VERSION ""

NS_ :

BS_:

BU_: STEERING_WHEEL HANDCART ECU TLM CHARGER ECU ECU HANDCART ECU LV CHARGER STEERING_WHEEL TLM HANDCART ECU HV CHARGER ECU HV HANDCART STEERING_WHEEL HV CHARGER ECU ECU HV ECU HV HANDCART ECU INVERTER_L HV HANDCART TLM ECU HV ECU HANDCART ECU TLM HV HANDCART ECU ECU HV ECU HANDCART HANDCART INVERTER_L ECU HANDCART HANDCART INVERTER_L HV HV ECU HV ECU INVERTER_L ECU HANDCART ECU HANDCART HV LV HV ECU LV ECU HANDCART LV HANDCART LV HV LV ECU LV HANDCART LV HV HV ECU HV HANDCART HV TLM TLM HV HV HV ECU HV HANDCART HV HV HV HV ECU HV HV HV TLM HANDCART ECU HV TLM HV ECU HV ECU TLM STEERING_WHEEL ECU HANDCART ECU HV ANY LV ANY ECU ANY LV ANY LV ANY STEERING_WHEEL ANY LV HV TLM LV HV TLM LV HV STEERING_WHEEL HV LV HV STEERING_WHEEL HV LV HV HV LV HV HANDCART ECU TLM CHARGER LV HV CHARGER LV HV HANDCART ECU TLM HANDCART LV HV CHARGER ECU HV CHARGER LV TLM HANDCART ECU HV CHARGER LV HV HANDCART ECU TLM CHARGER TLM HV HANDCART STEERING_WHEEL TLM CHARGER LV LV HANDCART HV LV TLM CHARGER LV LV HANDCART ECU TLM CHARGER ECU LV HANDCART LV TLM CHARGER TLM ECU HANDCART STEERING_WHEEL TLM HANDCART HANDCART ECU CHARGER HANDCART TLM HANDCART TLM ECU CHARGER HANDCART TLM HANDCART ECU STEERING_WHEEL CHARGER STEERING_WHEEL TLM CHARGER ECU STEERING_WHEEL HANDCART ECU TLM CHARGER ECU STEERING_WHEEL

BO_ 1818 NLG5_DIAG_TX: 8 NLG5
 SG_ LAD_D_ParamRp : 7|64@0+ (1,0) [0|0] "" Vector__XXX

BO_ 1816 NLG5_DIAG_RX: 8 Control
 SG_ LAD_D_ParamRq : 7|64@0+ (1,0) [0|0] "" Vector__XXX

BO_ 1556 NLG5_ERR: 5 NLG5
 SG_ NLG5_W_SC_M : 32|1@0+ (1,0) [0|0] ""  Control
 SG_ NLG5_W_OD : 33|1@0+ (1,0) [0|0] "" Vector__XXX
 SG_ NLG5_W_CM_NA : 35|1@0+ (1,0) [0|0] "" Vector__XXX
 SG_ NLG5_W_C_VOR : 36|1@0+ (1,0) [0|1] ""  Control
 SG_ NLG5_W_PL_IT : 37|1@0+ (1,0) [0|1] ""  Control
 SG_ NLG5_W_PL_BV : 38|1@0+ (1,0) [0|1] ""  Control
 SG_ NLG5_W_PL_MV : 39|1@0+ (1,0) [0|1] ""  Control
 SG_ NLG5_E_SDT_CT : 26|1@0+ (1,0) [0|1] ""  Control
 SG_ NLG5_E_SDT_AH : 27|1@0+ (1,0) [0|1] ""  Control
 SG_ NLG5_E_SDT_BV : 28|1@0+ (1,0) [0|1] ""  Control
 SG_ NLG5_E_SDT_BT : 29|1@0+ (1,0) [0|1] ""  Control
 SG_ NLG5_E_C_RX : 30|1@0+ (1,0) [0|1] ""  Control
 SG_ NLG5_E_C_TX : 31|1@0+ (1,0) [0|1] ""  Control
 SG_ NLG5_E_C_OFF : 16|1@0+ (1,0) [0|1] ""  Control
 SG_ NLG5_E_C_TO : 17|1@0+ (1,0) [0|1] ""  Control
 SG_ NLG5_E_INIT : 18|1@0+ (1,0) [0|1] ""  Control
 SG_ NLG5_E_WDT : 19|1@0+ (1,0) [0|1] ""  Control
 SG_ NLG5_E_EP_CRC : 20|1@0+ (1,0) [0|1] ""  Control
 SG_ NLG5_E_ES_CRC : 21|1@0+ (1,0) [0|1] ""  Control
 SG_ NLG5_E_NV_CRC : 22|1@0+ (1,0) [0|1] ""  Control
 SG_ NLG5_E_F_CRC : 23|1@0+ (1,0) [0|1] ""  Control
 SG_ NLG5_E_T_EXT3 : 8|1@0+ (1,0) [0|1] ""  Control
 SG_ NLG5_E_T_EXT2 : 9|1@0+ (1,0) [0|1] ""  Control
 SG_ NLG5_E_T_EXT1 : 10|1@0+ (1,0) [0|1] ""  Control
 SG_ NLG5_E_T_TR : 11|1@0+ (1,0) [0|1] ""  Control
 SG_ NLG5_E_T_DIO : 12|1@0+ (1,0) [0|1] ""  Control
 SG_ NLG5_E_T_POW : 13|1@0+ (1,0) [0|1] ""  Control
 SG_ NLG5_E_T_C : 14|1@0+ (1,0) [0|1] ""  Control
 SG_ NLG5_E_B_P : 15|1@0+ (1,0) [0|1] ""  Control
 SG_ NLG5_E_MF : 0|1@0+ (1,0) [0|1] ""  Control
 SG_ NLG5_E_OF : 1|1@0+ (1,0) [0|1] ""  Control
 SG_ NLG5_E_P_MV : 2|1@0+ (1,0) [0|1] ""  Control
 SG_ NLG5_E_P_OM : 3|1@0+ (1,0) [0|1] ""  Control
 SG_ NLG5_E_SC : 4|1@0+ (1,0) [0|1] ""  Control
 SG_ NLG5_E_MOV_I : 5|1@0+ (1,0) [0|1] ""  Control
 SG_ NLG5_E_MOV_II : 6|1@0+ (1,0) [0|1] ""  Control
 SG_ NLG5_E_OOV : 7|1@0+ (1,0) [0|1] ""  Control

BO_ 1555 NLG5_TEMP: 8 NLG5
 SG_ NLG5_TMP_EXT3 : 55|16@0- (0.1,0) [-40|300] "°C"  Control
 SG_ NLG5_TEMP_EXT2 : 39|16@0- (0.1,0) [-40|300] "°C"  Control
 SG_ NLG5_TMP_EXT1 : 23|16@0- (0.1,0) [-40|300] "°C"  Control
 SG_ NLG5_P_TMP : 7|16@0- (0.1,0) [-40|300] "°C"  Control

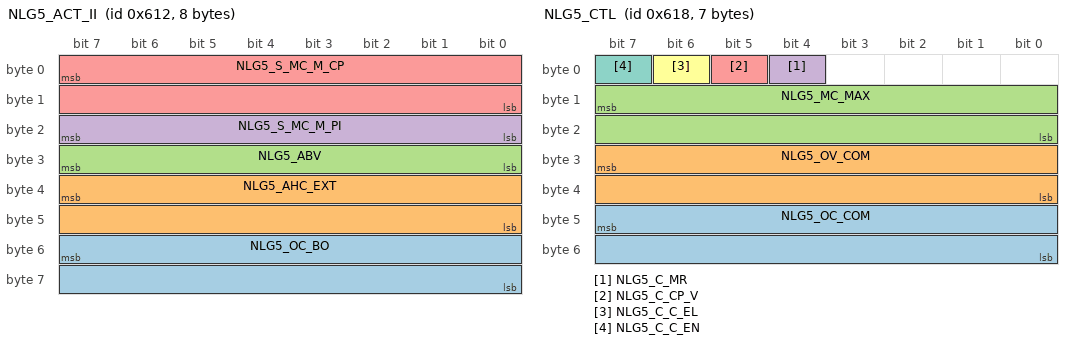
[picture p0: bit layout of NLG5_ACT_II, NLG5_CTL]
BO_ 1554 NLG5_ACT_II: 8 NLG5
 SG_ NLG5_OC_BO : 55|16@0+ (0.01,0) [0|50] "A"  Control
 SG_ NLG5_AHC_EXT : 39|16@0- (0.01,0) [-327.68|327.67] "Ah"  Control
 SG_ NLG5_ABV : 31|8@0+ (0.1,0) [0|25] "V"  Control
 SG_ NLG5_S_MC_M_PI : 23|8@0+ (0.1,0) [0|20] "A"  Control
 SG_ NLG5_S_MC_M_CP : 7|16@0+ (0.1,0) [0|100] "A"  Control

BO_ 1553 NLG5_ACT_I: 8 NLG5
 SG_ NLG5_OC_ACT : 55|16@0- (0.01,0) [0|150] "A"  Control
 SG_ NLG5_OV_ACT : 39|16@0+ (0.1,0) [0|1000] "V"  Control
 SG_ NLG5_MV_ACT : 23|16@0+ (0.1,0) [0|500] "V"  Control
 SG_ NLG5_MC_ACT : 7|16@0+ (0.01,0) [0|50] "A"  Control

BO_ 1552 NLG5_ST: 4 NLG5
 SG_ NLG5_S_AAC : 24|1@0+ (1,0) [0|1] ""  Control
 SG_ NLG5_S_L_T_BATT : 16|1@0+ (1,0) [0|1] ""  Control
 SG_ NLG5_S_L_T_TR : 17|1@0+ (1,0) [0|1] ""  Control
 SG_ NLG5_S_L_T_DIO : 18|1@0+ (1,0) [0|1] ""  Control
 SG_ NLG5_S_L_T_POW : 19|1@0+ (1,0) [0|1] ""  Control
 SG_ NLG5_S_L_T_CPRIM : 20|1@0+ (1,0) [0|1] ""  Control
 SG_ NLG5_S_L_MO_MAX : 21|1@0+ (1,0) [0|1] ""  Control
 SG_ NLG5_S_L_OC_MAX : 22|1@0+ (1,0) [0|1] ""  Control
 SG_ NLG5_S_L_MC_MAX : 23|1@0+ (1,0) [0|1] ""  Control
 SG_ NLG5_S_L_PMAX : 8|1@0+ (1,0) [0|1] ""  Control
 SG_ NLG5_S_L_CP : 9|1@0+ (1,0) [0|1] ""  Control
 SG_ NLG5_S_L_PI : 10|1@0+ (1,0) [0|1] ""  Control
 SG_ NLG5_S_L_MC : 11|1@0+ (1,0) [0|1] ""  Control
 SG_ NLG5_S_L_OC : 12|1@0+ (1,0) [0|1] ""  Control
 SG_ NLG5_S_L_OV : 13|1@0+ (1,0) [0|1] ""  Control
 SG_ NLG5_S_BPD_II : 14|1@0+ (1,0) [0|1] ""  Control
 SG_ NLG5_S_BPD_I : 15|1@0+ (1,0) [0|1] ""  Control
 SG_ NLG5_S_CP_DT : 0|1@0+ (1,0) [0|1] ""  Control
 SG_ NLG5_S_UM_II : 1|1@0+ (1,0) [0|1] ""  Control
 SG_ NLG5_S_UM_I : 2|1@0+ (1,0) [0|1] ""  Control
 SG_ NLG5_S_EUM : 3|1@0+ (1,0) [0|1] ""  Control
 SG_ NLG5_S_FAN : 4|1@0+ (1,0) [0|1] ""  Control
 SG_ NLG5_S_WAR : 5|1@0+ (1,0) [0|1] ""  Control
 SG_ NLG5_S_ERR : 6|1@0+ (1,0) [0|1] ""  Control
 SG_ NLG5_S_HE : 7|1@0+ (1,0) [0|1] ""  Control

BO_ 1560 NLG5_CTL: 7 Control
 SG_ NLG5_OC_COM : 47|16@0+ (0.1,0) [0|150] "A"  NLG5
 SG_ NLG5_OV_COM : 31|16@0+ (0.1,0) [0|1000] "V"  NLG5
 SG_ NLG5_MC_MAX : 15|16@0+ (0.1,0) [0|50] "A"  NLG5
 SG_ NLG5_C_MR : 4|1@0+ (1,0) [0|1] ""  NLG5
 SG_ NLG5_C_CP_V : 5|1@0+ (1,0) [0|1] ""  NLG5
 SG_ NLG5_C_C_EL : 6|1@0+ (1,0) [0|1] ""  NLG5
 SG_ NLG5_C_C_EN : 7|1@0+ (1,0) [0|1] ""  NLG5

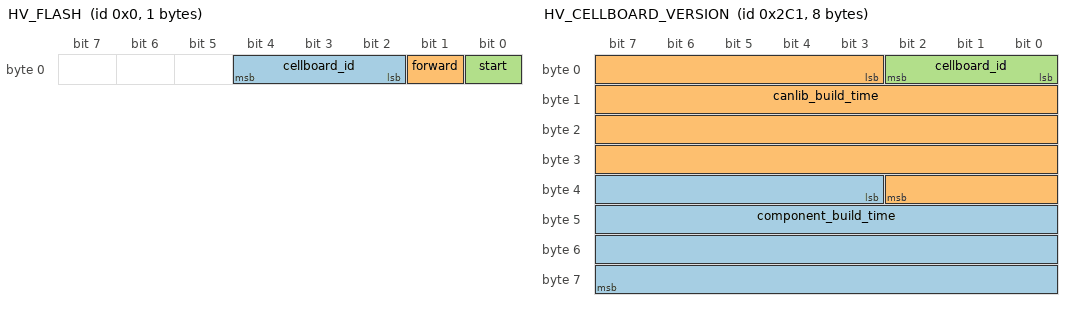
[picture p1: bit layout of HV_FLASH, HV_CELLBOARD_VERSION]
BO_ 0 HV_FLASH: 1 Vector__XXX
 SG_ cellboard_id : 2|3@1+ (1,0) [0|7] "" Vector__XXX
 SG_ forward : 1|1@1+ (1,0) [0|1] "" Vector__XXX
 SG_ start : 0|1@1+ (1,0) [0|1] "" Vector__XXX

BO_ 1 HV_FLASH_MAINBOARD_TX: 0 Vector__XXX

BO_ 2 HV_FLASH_MAINBOARD_RX: 0 Vector__XXX

BO_ 4 HV_FLASH_CELLBOARD_0_TX: 0 Vector__XXX

BO_ 5 HV_FLASH_CELLBOARD_0_RX: 0 Vector__XXX

BO_ 6 HV_FLASH_CELLBOARD_1_TX: 0 Vector__XXX

BO_ 7 HV_FLASH_CELLBOARD_1_RX: 0 Vector__XXX

BO_ 8 HV_FLASH_CELLBOARD_2_TX: 0 Vector__XXX

BO_ 9 HV_FLASH_CELLBOARD_2_RX: 0 Vector__XXX

BO_ 10 HV_FLASH_CELLBOARD_3_TX: 0 Vector__XXX

BO_ 11 HV_FLASH_CELLBOARD_3_RX: 0 Vector__XXX

BO_ 12 HV_FLASH_CELLBOARD_4_TX: 0 Vector__XXX

BO_ 13 HV_FLASH_CELLBOARD_4_RX: 0 Vector__XXX

BO_ 14 HV_FLASH_CELLBOARD_5_TX: 0 Vector__XXX

BO_ 15 HV_FLASH_CELLBOARD_5_RX: 0 Vector__XXX

BO_ 16 LV_JMP_TO_BLT: 0 Vector__XXX

BO_ 17 LV_FLASH_TX: 0 Vector__XXX

BO_ 18 LV_FLASH_RX: 0 Vector__XXX

BO_ 19 ECU_JMP_TO_BLT: 0 Vector__XXX

BO_ 20 ECU_FLASH_TX: 0 Vector__XXX

BO_ 21 ECU_FLASH_RX: 0 Vector__XXX

BO_ 22 STEERING_WHEEL_JMP_TO_BLT: 0 Vector__XXX

BO_ 23 STEERING_WHEEL_FLASH_TX: 0 Vector__XXX

BO_ 24 STEERING_WHEEL_FLASH_RX: 0 Vector__XXX

BO_ 700 STEERING_WHEEL_VERSION: 8 Vector__XXX
 SG_ canlib_build_time : 32|32@1+ (1,0) [0|4294967295] "" Vector__XXX
 SG_ component_build_time : 0|32@1+ (1,0) [0|4294967295] "" Vector__XXX

BO_ 701 ECU_VERSION: 8 Vector__XXX
 SG_ canlib_build_time : 32|32@1+ (1,0) [0|4294967295] "" Vector__XXX
 SG_ component_build_time : 0|32@1+ (1,0) [0|4294967295] "" Vector__XXX

BO_ 703 LV_VERSION: 8 Vector__XXX
 SG_ canlib_build_time : 32|32@1+ (1,0) [0|4294967295] "" Vector__XXX
 SG_ component_build_time : 0|32@1+ (1,0) [0|4294967295] "" Vector__XXX

BO_ 704 TLM_VERSION: 8 Vector__XXX
 SG_ canlib_build_time : 32|32@1+ (1,0) [0|4294967295] "" Vector__XXX
 SG_ component_build_time : 0|32@1+ (1,0) [0|4294967295] "" Vector__XXX

BO_ 702 HV_MAINBOARD_VERSION: 8 Vector__XXX
 SG_ canlib_build_time : 32|32@1+ (1,0) [0|4294967295] "" Vector__XXX
 SG_ component_build_time : 0|32@1+ (1,0) [0|4294967295] "" Vector__XXX

BO_ 705 HV_CELLBOARD_VERSION: 8 Vector__XXX
 SG_ component_build_time : 35|29@1+ (1,0) [0|536870911] "" Vector__XXX
 SG_ canlib_build_time : 3|32@1+ (1,0) [0|4294967295] "" Vector__XXX
 SG_ cellboard_id : 0|3@1+ (1,0) [0|7] "" Vector__XXX

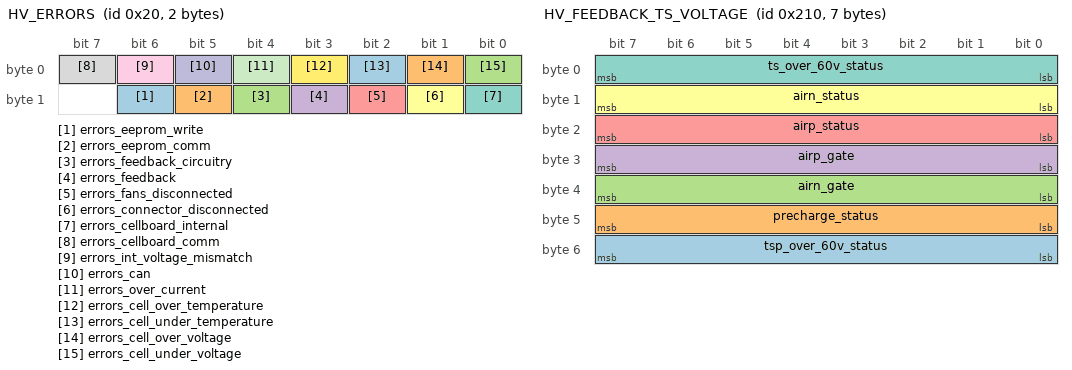
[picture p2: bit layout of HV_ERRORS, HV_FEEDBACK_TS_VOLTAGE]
BO_ 32 HV_ERRORS: 2 Vector__XXX
 SG_ errors_eeprom_write : 14|1@1+ (1,0) [0|1] "" Vector__XXX
 SG_ errors_eeprom_comm : 13|1@1+ (1,0) [0|1] "" Vector__XXX
 SG_ errors_feedback_circuitry : 12|1@1+ (1,0) [0|1] "" Vector__XXX
 SG_ errors_feedback : 11|1@1+ (1,0) [0|1] "" Vector__XXX
 SG_ errors_fans_disconnected : 10|1@1+ (1,0) [0|1] "" Vector__XXX
 SG_ errors_connector_disconnected : 9|1@1+ (1,0) [0|1] "" Vector__XXX
 SG_ errors_cellboard_internal : 8|1@1+ (1,0) [0|1] "" Vector__XXX
 SG_ errors_cellboard_comm : 7|1@1+ (1,0) [0|1] "" Vector__XXX
 SG_ errors_int_voltage_mismatch : 6|1@1+ (1,0) [0|1] "" Vector__XXX
 SG_ errors_can : 5|1@1+ (1,0) [0|1] "" Vector__XXX
 SG_ errors_over_current : 4|1@1+ (1,0) [0|1] "" Vector__XXX
 SG_ errors_cell_over_temperature : 3|1@1+ (1,0) [0|1] "" Vector__XXX
 SG_ errors_cell_under_temperature : 2|1@1+ (1,0) [0|1] "" Vector__XXX
 SG_ errors_cell_over_voltage : 1|1@1+ (1,0) [0|1] "" Vector__XXX
 SG_ errors_cell_under_voltage : 0|1@1+ (1,0) [0|1] "" Vector__XXX

BO_ 512 HV_DEBUG_SIGNALS: 5 Vector__XXX
 SG_ errors_eeprom_write : 34|1@1+ (1,0) [0|1] "" Vector__XXX
 SG_ errors_eeprom_comm : 33|1@1+ (1,0) [0|1] "" Vector__XXX
 SG_ errors_feedback_circuitry : 32|1@1+ (1,0) [0|1] "" Vector__XXX
 SG_ errors_feedback : 31|1@1+ (1,0) [0|1] "" Vector__XXX
 SG_ errors_fans_disconnected : 30|1@1+ (1,0) [0|1] "" Vector__XXX
 SG_ errors_connector_disconnected : 29|1@1+ (1,0) [0|1] "" Vector__XXX
 SG_ errors_cellboard_internal : 28|1@1+ (1,0) [0|1] "" Vector__XXX
 SG_ errors_cellboard_comm : 27|1@1+ (1,0) [0|1] "" Vector__XXX
 SG_ errors_int_voltage_mismatch : 26|1@1+ (1,0) [0|1] "" Vector__XXX
 SG_ errors_can : 25|1@1+ (1,0) [0|1] "" Vector__XXX
 SG_ errors_over_current : 24|1@1+ (1,0) [0|1] "" Vector__XXX
 SG_ errors_cell_over_temperature : 23|1@1+ (1,0) [0|1] "" Vector__XXX
 SG_ errors_cell_under_temperature : 22|1@1+ (1,0) [0|1] "" Vector__XXX
 SG_ errors_cell_over_voltage : 21|1@1+ (1,0) [0|1] "" Vector__XXX
 SG_ errors_cell_under_voltage : 20|1@1+ (1,0) [0|1] "" Vector__XXX
 SG_ feedbacks_sd_imd : 19|1@1+ (1,0) [0|1] "" Vector__XXX
 SG_ feedbacks_sd_bms : 18|1@1+ (1,0) [0|1] "" Vector__XXX
 SG_ feedbacks_sd_in : 17|1@1+ (1,0) [0|1] "" Vector__XXX
 SG_ feedbacks_sd_out : 16|1@1+ (1,0) [0|1] "" Vector__XXX
 SG_ feedbacks_sd_end : 15|1@1+ (1,0) [0|1] "" Vector__XXX
 SG_ feedbacks_check_mux : 14|1@1+ (1,0) [0|1] "" Vector__XXX
 SG_ feedbacks_imd_fault : 13|1@1+ (1,0) [0|1] "" Vector__XXX
 SG_ feedbacks_tsp_over_60v_status : 12|1@1+ (1,0) [0|1] "" Vector__XXX
 SG_ feedbacks_precharge_status : 11|1@1+ (1,0) [0|1] "" Vector__XXX
 SG_ feedbacks_airn_gate : 10|1@1+ (1,0) [0|1] "" Vector__XXX
 SG_ feedbacks_airp_gate : 9|1@1+ (1,0) [0|1] "" Vector__XXX
 SG_ feedbacks_airp_status : 8|1@1+ (1,0) [0|1] "" Vector__XXX
 SG_ feedbacks_airn_status : 7|1@1+ (1,0) [0|1] "" Vector__XXX
 SG_ feedbacks_ts_over_60v_status : 6|1@1+ (1,0) [0|1] "" Vector__XXX
 SG_ feedbacks_tsal_green : 5|1@1+ (1,0) [0|1] "" Vector__XXX
 SG_ feedbacks_ext_latched : 4|1@1+ (1,0) [0|1] "" Vector__XXX
 SG_ feedbacks_bms_cockpit : 3|1@1+ (1,0) [0|1] "" Vector__XXX
 SG_ feedbacks_tsal_green_fault_latched : 2|1@1+ (1,0) [0|1] "" Vector__XXX
 SG_ feedbacks_imd_cockpit : 1|1@1+ (1,0) [0|1] "" Vector__XXX
 SG_ feedbacks_implausibility_detected : 0|1@1+ (1,0) [0|1] "" Vector__XXX

BO_ 1536 HV_FANS_STATUS: 3 Vector__XXX
 SG_ fans_speed : 1|16@1+ (1.5259021896696422e-05,0) [0|1] "" Vector__XXX
 SG_ fans_override : 0|1@1+ (1,0) [0|1] "" Vector__XXX

BO_ 1024 HV_SET_FANS_STATUS: 3 Vector__XXX
 SG_ fans_speed : 1|16@1+ (1.5259021896696422e-05,0) [0|1] "" Vector__XXX
 SG_ fans_override : 0|1@1+ (1,0) [0|1] "" Vector__XXX

BO_ 520 HV_FEEDBACK_STATUS: 8 Vector__XXX
 SG_ feedback_check_mux : 62|2@1+ (1,0) [0|3] "" Vector__XXX
 SG_ feedback_tsp_over_60v_status : 60|2@1+ (1,0) [0|3] "" Vector__XXX
 SG_ feedback_precharge_status : 58|2@1+ (1,0) [0|3] "" Vector__XXX
 SG_ feedback_ext_latched : 56|2@1+ (1,0) [0|3] "" Vector__XXX
 SG_ feedback_tsal_green_fault_latched : 54|2@1+ (1,0) [0|3] "" Vector__XXX
 SG_ v5_mcu : 52|2@1+ (1,0) [0|3] "" Vector__XXX
 SG_ sd_end : 50|2@1+ (1,0) [0|3] "" Vector__XXX
 SG_ sd_in : 48|2@1+ (1,0) [0|3] "" Vector__XXX
 SG_ sd_out : 46|2@1+ (1,0) [0|3] "" Vector__XXX
 SG_ probing_3v3 : 44|2@1+ (1,0) [0|3] "" Vector__XXX
 SG_ tsal_green : 42|2@1+ (1,0) [0|3] "" Vector__XXX
 SG_ plausible_state_rc : 40|2@1+ (1,0) [0|3] "" Vector__XXX
 SG_ imd_ok : 38|2@1+ (1,0) [0|3] "" Vector__XXX
 SG_ not_ext_fault_latched : 36|2@1+ (1,0) [0|3] "" Vector__XXX
 SG_ not_imd_fault_latched : 34|2@1+ (1,0) [0|3] "" Vector__XXX
 SG_ not_bms_fault_latched : 32|2@1+ (1,0) [0|3] "" Vector__XXX
 SG_ plausible_state_latched : 30|2@1+ (1,0) [0|3] "" Vector__XXX
 SG_ not_latch_reset : 28|2@1+ (1,0) [0|3] "" Vector__XXX
 SG_ indicator_connected : 26|2@1+ (1,0) [0|3] "" Vector__XXX
 SG_ not_imd_fault_cockpit_led : 24|2@1+ (1,0) [0|3] "" Vector__XXX
 SG_ not_bms_fault_cockpit_led : 22|2@1+ (1,0) [0|3] "" Vector__XXX
 SG_ plausible_state : 20|2@1+ (1,0) [0|3] "" Vector__XXX
 SG_ plausible_state_persisted : 18|2@1+ (1,0) [0|3] "" Vector__XXX
 SG_ ts_less_than_60v : 16|2@1+ (1,0) [0|3] "" Vector__XXX
 SG_ sd_bms_fb : 14|2@1+ (1,0) [0|3] "" Vector__XXX
 SG_ sd_imd_fb : 12|2@1+ (1,0) [0|3] "" Vector__XXX
 SG_ airp_open_mec : 10|2@1+ (1,0) [0|3] "" Vector__XXX
 SG_ precharge_open_mec : 8|2@1+ (1,0) [0|3] "" Vector__XXX
 SG_ airn_open_mec : 6|2@1+ (1,0) [0|3] "" Vector__XXX
 SG_ airp_open_com : 4|2@1+ (1,0) [0|3] "" Vector__XXX
 SG_ precharge_open_com : 2|2@1+ (1,0) [0|3] "" Vector__XXX
 SG_ airn_open_com : 0|2@1+ (1,0) [0|3] "" Vector__XXX

BO_ 528 HV_FEEDBACK_TS_VOLTAGE: 7 Vector__XXX
 SG_ tsp_over_60v_status : 48|8@1+ (0.012941176470588235,0) [0|3.3] "" Vector__XXX
 SG_ precharge_status : 40|8@1+ (0.012941176470588235,0) [0|3.3] "" Vector__XXX
 SG_ airn_gate : 32|8@1+ (0.012941176470588235,0) [0|3.3] "" Vector__XXX
 SG_ airp_gate : 24|8@1+ (0.012941176470588235,0) [0|3.3] "" Vector__XXX
 SG_ airp_status : 16|8@1+ (0.012941176470588235,0) [0|3.3] "" Vector__XXX
 SG_ airn_status : 8|8@1+ (0.012941176470588235,0) [0|3.3] "" Vector__XXX
 SG_ ts_over_60v_status : 0|8@1+ (0.012941176470588235,0) [0|3.3] "" Vector__XXX

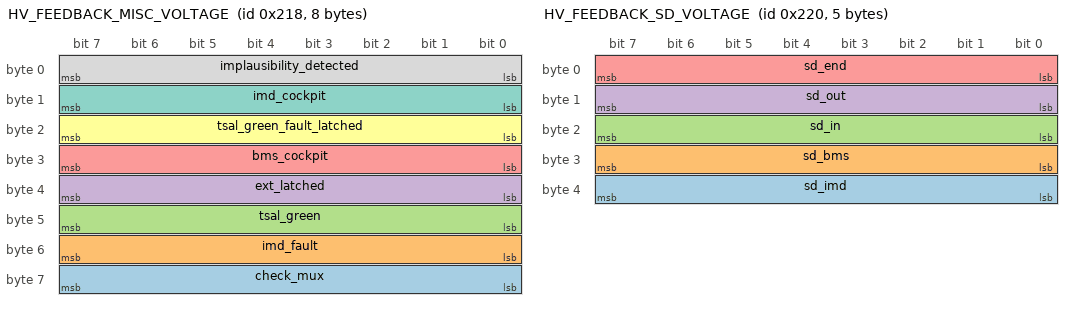
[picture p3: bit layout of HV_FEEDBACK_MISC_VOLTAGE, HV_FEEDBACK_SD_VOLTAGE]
BO_ 536 HV_FEEDBACK_MISC_VOLTAGE: 8 Vector__XXX
 SG_ check_mux : 56|8@1+ (0.012941176470588235,0) [0|3.3] "" Vector__XXX
 SG_ imd_fault : 48|8@1+ (0.012941176470588235,0) [0|3.3] "" Vector__XXX
 SG_ tsal_green : 40|8@1+ (0.012941176470588235,0) [0|3.3] "" Vector__XXX
 SG_ ext_latched : 32|8@1+ (0.012941176470588235,0) [0|3.3] "" Vector__XXX
 SG_ bms_cockpit : 24|8@1+ (0.012941176470588235,0) [0|3.3] "" Vector__XXX
 SG_ tsal_green_fault_latched : 16|8@1+ (0.012941176470588235,0) [0|3.3] "" Vector__XXX
 SG_ imd_cockpit : 8|8@1+ (0.012941176470588235,0) [0|3.3] "" Vector__XXX
 SG_ implausibility_detected : 0|8@1+ (0.012941176470588235,0) [0|3.3] "" Vector__XXX

BO_ 544 HV_FEEDBACK_SD_VOLTAGE: 5 Vector__XXX
 SG_ sd_imd : 32|8@1+ (0.012941176470588235,0) [0|3.3] "" Vector__XXX
 SG_ sd_bms : 24|8@1+ (0.012941176470588235,0) [0|3.3] "" Vector__XXX
 SG_ sd_in : 16|8@1+ (0.012941176470588235,0) [0|3.3] "" Vector__XXX
 SG_ sd_out : 8|8@1+ (0.012941176470588235,0) [0|3.3] "" Vector__XXX
 SG_ sd_end : 0|8@1+ (0.012941176470588235,0) [0|3.3] "" Vector__XXX

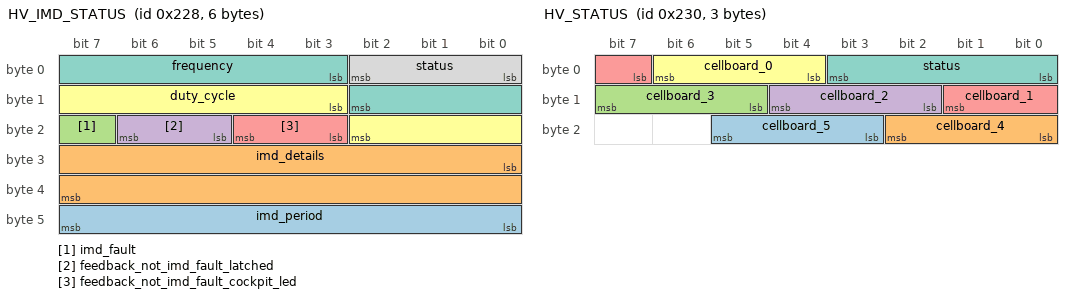
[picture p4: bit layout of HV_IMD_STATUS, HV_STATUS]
BO_ 552 HV_IMD_STATUS: 6 Vector__XXX
 SG_ imd_period : 40|8@1+ (1,0) [0|255] "" Vector__XXX
 SG_ imd_details : 24|16@1+ (1,0) [0|65535] "" Vector__XXX
 SG_ imd_fault : 23|1@1+ (1,0) [0|1] "" Vector__XXX
 SG_ feedback_not_imd_fault_latched : 21|2@1+ (1,0) [0|3] "" Vector__XXX
 SG_ feedback_not_imd_fault_cockpit_led : 19|2@1+ (1,0) [0|3] "" Vector__XXX
 SG_ duty_cycle : 11|8@1+ (0.00392156862745098,0) [0|1] "" Vector__XXX
 SG_ frequency : 3|8@1+ (0.23529411764705882,0.0) [0.0|60.0] "" Vector__XXX
 SG_ status : 0|3@1+ (1,0) [0|7] "" Vector__XXX

BO_ 560 HV_STATUS: 3 Vector__XXX
 SG_ cellboard_5 : 19|3@1+ (1,0) [0|7] "" Vector__XXX
 SG_ cellboard_4 : 16|3@1+ (1,0) [0|7] "" Vector__XXX
 SG_ cellboard_3 : 13|3@1+ (1,0) [0|7] "" Vector__XXX
 SG_ cellboard_2 : 10|3@1+ (1,0) [0|7] "" Vector__XXX
 SG_ cellboard_1 : 7|3@1+ (1,0) [0|7] "" Vector__XXX
 SG_ cellboard_0 : 4|3@1+ (1,0) [0|7] "" Vector__XXX
 SG_ status : 0|4@1+ (1,0) [0|15] "" Vector__XXX

BO_ 40 HV_SET_STATUS_ECU: 1 Vector__XXX
 SG_ hv_status_set : 1|1@1+ (1,0) [0|1] "" Vector__XXX
 SG_ status : 0|1@1+ (1,0) [0|1] "" Vector__XXX

BO_ 48 HV_SET_STATUS_HANDCART: 1 Vector__XXX
 SG_ hv_status_set : 1|1@1+ (1,0) [0|1] "" Vector__XXX
 SG_ status : 0|1@1+ (1,0) [0|1] "" Vector__XXX

BO_ 1544 HV_BALANCING_STATUS: 8 Vector__XXX
 SG_ discharging_cell_23 : 56|1@1+ (1,0) [0|1] "" Vector__XXX
 SG_ discharging_cell_22 : 55|1@1+ (1,0) [0|1] "" Vector__XXX
 SG_ discharging_cell_21 : 54|1@1+ (1,0) [0|1] "" Vector__XXX
 SG_ discharging_cell_20 : 53|1@1+ (1,0) [0|1] "" Vector__XXX
 SG_ discharging_cell_19 : 52|1@1+ (1,0) [0|1] "" Vector__XXX
 SG_ discharging_cell_18 : 51|1@1+ (1,0) [0|1] "" Vector__XXX
 SG_ discharging_cell_17 : 50|1@1+ (1,0) [0|1] "" Vector__XXX
 SG_ discharging_cell_16 : 49|1@1+ (1,0) [0|1] "" Vector__XXX
 SG_ discharging_cell_15 : 48|1@1+ (1,0) [0|1] "" Vector__XXX
 SG_ discharging_cell_14 : 47|1@1+ (1,0) [0|1] "" Vector__XXX
 SG_ discharging_cell_13 : 46|1@1+ (1,0) [0|1] "" Vector__XXX
 SG_ discharging_cell_12 : 45|1@1+ (1,0) [0|1] "" Vector__XXX
 SG_ discharging_cell_11 : 44|1@1+ (1,0) [0|1] "" Vector__XXX
 SG_ discharging_cell_10 : 43|1@1+ (1,0) [0|1] "" Vector__XXX
 SG_ discharging_cell_9 : 42|1@1+ (1,0) [0|1] "" Vector__XXX
 SG_ discharging_cell_8 : 41|1@1+ (1,0) [0|1] "" Vector__XXX
 SG_ discharging_cell_7 : 40|1@1+ (1,0) [0|1] "" Vector__XXX
 SG_ discharging_cell_6 : 39|1@1+ (1,0) [0|1] "" Vector__XXX
 SG_ discharging_cell_5 : 38|1@1+ (1,0) [0|1] "" Vector__XXX
 SG_ discharging_cell_4 : 37|1@1+ (1,0) [0|1] "" Vector__XXX
 SG_ discharging_cell_3 : 36|1@1+ (1,0) [0|1] "" Vector__XXX
 SG_ discharging_cell_2 : 35|1@1+ (1,0) [0|1] "" Vector__XXX
 SG_ discharging_cell_1 : 34|1@1+ (1,0) [0|1] "" Vector__XXX
 SG_ discharging_cell_0 : 33|1@1+ (1,0) [0|1] "" Vector__XXX
 SG_ status : 31|2@1+ (1,0) [0|3] "" Vector__XXX
 SG_ balancing_cells_cell17 : 30|1@1+ (1,0) [0|1] "" Vector__XXX
 SG_ balancing_cells_cell16 : 29|1@1+ (1,0) [0|1] "" Vector__XXX
 SG_ balancing_cells_cell15 : 28|1@1+ (1,0) [0|1] "" Vector__XXX
 SG_ balancing_cells_cell14 : 27|1@1+ (1,0) [0|1] "" Vector__XXX
 SG_ balancing_cells_cell13 : 26|1@1+ (1,0) [0|1] "" Vector__XXX
 SG_ balancing_cells_cell12 : 25|1@1+ (1,0) [0|1] "" Vector__XXX
 SG_ balancing_cells_cell11 : 24|1@1+ (1,0) [0|1] "" Vector__XXX
 SG_ balancing_cells_cell10 : 23|1@1+ (1,0) [0|1] "" Vector__XXX
 SG_ balancing_cells_cell9 : 22|1@1+ (1,0) [0|1] "" Vector__XXX
 SG_ balancing_cells_cell8 : 21|1@1+ (1,0) [0|1] "" Vector__XXX
 SG_ balancing_cells_cell7 : 20|1@1+ (1,0) [0|1] "" Vector__XXX
 SG_ balancing_cells_cell6 : 19|1@1+ (1,0) [0|1] "" Vector__XXX
 SG_ balancing_cells_cell5 : 18|1@1+ (1,0) [0|1] "" Vector__XXX
 SG_ balancing_cells_cell4 : 17|1@1+ (1,0) [0|1] "" Vector__XXX
 SG_ balancing_cells_cell3 : 16|1@1+ (1,0) [0|1] "" Vector__XXX
 SG_ balancing_cells_cell2 : 15|1@1+ (1,0) [0|1] "" Vector__XXX
 SG_ balancing_cells_cell1 : 14|1@1+ (1,0) [0|1] "" Vector__XXX
 SG_ balancing_cells_cell0 : 13|1@1+ (1,0) [0|1] "" Vector__XXX
 SG_ errors_open_wire : 12|1@1+ (1,0) [0|1] "" Vector__XXX
 SG_ errors_temp_comm_5 : 11|1@1+ (1,0) [0|1] "" Vector__XXX
 SG_ errors_temp_comm_4 : 10|1@1+ (1,0) [0|1] "" Vector__XXX
 SG_ errors_temp_comm_3 : 9|1@1+ (1,0) [0|1] "" Vector__XXX
 SG_ errors_temp_comm_2 : 8|1@1+ (1,0) [0|1] "" Vector__XXX
 SG_ errors_temp_comm_1 : 7|1@1+ (1,0) [0|1] "" Vector__XXX
 SG_ errors_temp_comm_0 : 6|1@1+ (1,0) [0|1] "" Vector__XXX
 SG_ errors_ltc_comm : 5|1@1+ (1,0) [0|1] "" Vector__XXX
 SG_ errors_can_comm : 4|1@1+ (1,0) [0|1] "" Vector__XXX
 SG_ balancing_status : 3|1@1+ (1,0) [0|1] "" Vector__XXX
 SG_ cellboard_id : 0|3@1+ (1,0) [0|7] "" Vector__XXX

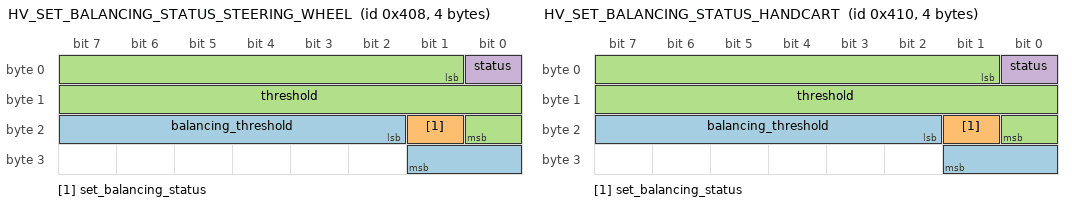
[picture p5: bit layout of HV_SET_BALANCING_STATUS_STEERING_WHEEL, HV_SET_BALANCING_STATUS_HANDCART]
BO_ 1032 HV_SET_BALANCING_STATUS_STEERING_WHEEL: 4 Vector__XXX
 SG_ balancing_threshold : 18|8@1+ (1,5) [5|200] "" Vector__XXX
 SG_ set_balancing_status : 17|1@1+ (1,0) [0|1] "" Vector__XXX
 SG_ threshold : 1|16@1+ (2.9755092698558025e-06,0.005) [0.005|0.2] "" Vector__XXX
 SG_ status : 0|1@1+ (1,0) [0|1] "" Vector__XXX

BO_ 1040 HV_SET_BALANCING_STATUS_HANDCART: 4 Vector__XXX
 SG_ balancing_threshold : 18|8@1+ (1,5) [5|200] "" Vector__XXX
 SG_ set_balancing_status : 17|1@1+ (1,0) [0|1] "" Vector__XXX
 SG_ threshold : 1|16@1+ (2.9755092698558025e-06,0.005) [0.005|0.2] "" Vector__XXX
 SG_ status : 0|1@1+ (1,0) [0|1] "" Vector__XXX

BO_ 568 LV_STATUS: 1 Vector__XXX
 SG_ status : 0|3@1+ (1,0) [0|7] "" Vector__XXX

BO_ 1568 LV_CHARGING_STATUS: 1 Vector__XXX
 SG_ status : 0|1@1+ (1,0) [0|1] "" Vector__XXX

BO_ 1576 LV_COOLING_AGGRESSIVENESS: 1 Vector__XXX
 SG_ status : 0|2@1+ (1,0) [0|3] "" Vector__XXX

BO_ 1048 LV_SET_COOLING_AGGRESSIVENESS: 1 Vector__XXX
 SG_ status : 0|2@1+ (1,0) [0|3] "" Vector__XXX

BO_ 1584 LV_RADIATOR_SPEED: 2 Vector__XXX
 SG_ radiator_speed : 2|8@1+ (0.007874015748031496,0) [0|1] "" Vector__XXX
 SG_ status : 0|2@1+ (1,0) [0|3] "" Vector__XXX

BO_ 1592 LV_PUMPS_SPEED: 2 Vector__XXX
 SG_ pumps_speed : 2|8@1+ (0.007874015748031496,0) [0|1] "" Vector__XXX
 SG_ status : 0|2@1+ (1,0) [0|3] "" Vector__XXX

BO_ 1056 LV_SET_RADIATOR_SPEED: 2 Vector__XXX
 SG_ radiator_speed : 2|8@1+ (0.007874015748031496,0) [0|1] "" Vector__XXX
 SG_ status : 0|2@1+ (1,0) [0|3] "" Vector__XXX

BO_ 1064 LV_SET_PUMPS_SPEED: 2 Vector__XXX
 SG_ pumps_speed : 2|8@1+ (0.007874015748031496,0) [0|1] "" Vector__XXX
 SG_ status : 0|2@1+ (1,0) [0|3] "" Vector__XXX

BO_ 576 LV_ERRORS: 3 Vector__XXX
 SG_ health_signals_sign_battery_current : 22|1@1+ (1,0) [0|1] "" Vector__XXX
 SG_ health_signals_battery_current : 21|1@1+ (1,0) [0|1] "" Vector__XXX
 SG_ health_signals_charger_current : 20|1@1+ (1,0) [0|1] "" Vector__XXX
 SG_ health_signals_battery_voltage_out : 19|1@1+ (1,0) [0|1] "" Vector__XXX
 SG_ health_signals_relay_out : 18|1@1+ (1,0) [0|1] "" Vector__XXX
 SG_ health_signals_lvms_out : 17|1@1+ (1,0) [0|1] "" Vector__XXX
 SG_ errors_mux : 16|1@1+ (1,0) [0|1] "" Vector__XXX
 SG_ errors_adc_init : 15|1@1+ (1,0) [0|1] "" Vector__XXX
 SG_ errors_pump : 14|1@1+ (1,0) [0|1] "" Vector__XXX
 SG_ errors_fan : 13|1@1+ (1,0) [0|1] "" Vector__XXX
 SG_ errors_radiator : 12|1@1+ (1,0) [0|1] "" Vector__XXX
 SG_ errors_mcp23017 : 11|1@1+ (1,0) [0|1] "" Vector__XXX
 SG_ errors_voltages_not_ready : 10|1@1+ (1,0) [0|1] "" Vector__XXX
 SG_ errors_bms_monitor : 9|1@1+ (1,0) [0|1] "" Vector__XXX
 SG_ errors_relay : 8|1@1+ (1,0) [0|1] "" Vector__XXX
 SG_ errors_cell_over_temperature : 7|1@1+ (1,0) [0|1] "" Vector__XXX
 SG_ errors_cell_under_temperature : 6|1@1+ (1,0) [0|1] "" Vector__XXX
 SG_ errors_over_current : 5|1@1+ (1,0) [0|1] "" Vector__XXX
 SG_ errors_spi : 4|1@1+ (1,0) [0|1] "" Vector__XXX
 SG_ errors_can : 3|1@1+ (1,0) [0|1] "" Vector__XXX
 SG_ errors_battery_open_wire : 2|1@1+ (1,0) [0|1] "" Vector__XXX
 SG_ errors_cell_overvoltage : 1|1@1+ (1,0) [0|1] "" Vector__XXX
 SG_ errors_cell_undervoltage : 0|1@1+ (1,0) [0|1] "" Vector__XXX

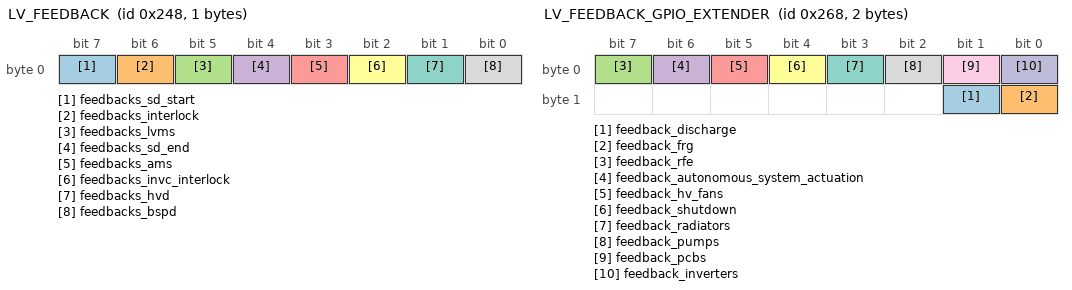
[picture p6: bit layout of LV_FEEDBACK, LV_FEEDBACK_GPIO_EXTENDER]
BO_ 584 LV_FEEDBACK: 1 Vector__XXX
 SG_ feedbacks_sd_start : 7|1@1+ (1,0) [0|1] "" Vector__XXX
 SG_ feedbacks_interlock : 6|1@1+ (1,0) [0|1] "" Vector__XXX
 SG_ feedbacks_lvms : 5|1@1+ (1,0) [0|1] "" Vector__XXX
 SG_ feedbacks_sd_end : 4|1@1+ (1,0) [0|1] "" Vector__XXX
 SG_ feedbacks_ams : 3|1@1+ (1,0) [0|1] "" Vector__XXX
 SG_ feedbacks_invc_interlock : 2|1@1+ (1,0) [0|1] "" Vector__XXX
 SG_ feedbacks_hvd : 1|1@1+ (1,0) [0|1] "" Vector__XXX
 SG_ feedbacks_bspd : 0|1@1+ (1,0) [0|1] "" Vector__XXX

BO_ 592 LV_FEEDBACK_TS_VOLTAGE: 8 Vector__XXX
 SG_ ams : 48|16@1+ (0.003418803418803419,0) [0|14] "" Vector__XXX
 SG_ invc_interlock : 32|16@1+ (0.003418803418803419,0) [0|14] "" Vector__XXX
 SG_ hvd : 16|16@1+ (0.003418803418803419,0) [0|14] "" Vector__XXX
 SG_ bspd : 0|16@1+ (0.003418803418803419,0) [0|14] "" Vector__XXX

BO_ 600 LV_FEEDBACK_SD_VOLTAGE: 8 Vector__XXX
 SG_ sd_start : 48|16@1+ (0.003418803418803419,0) [0|14] "" Vector__XXX
 SG_ interlock : 32|16@1+ (0.003418803418803419,0) [0|14] "" Vector__XXX
 SG_ lvms : 16|16@1+ (0.003418803418803419,0) [0|14] "" Vector__XXX
 SG_ sd_end : 0|16@1+ (0.003418803418803419,0) [0|14] "" Vector__XXX

BO_ 608 LV_FEEDBACK_ENCLOSURE_VOLTAGE: 8 Vector__XXX
 SG_ backplate : 48|16@1+ (0.003418803418803419,0) [0|14] "" Vector__XXX
 SG_ hv_encl_2 : 32|16@1+ (0.003418803418803419,0) [0|14] "" Vector__XXX
 SG_ invc_lid : 16|16@1+ (0.003418803418803419,0) [0|14] "" Vector__XXX
 SG_ lv_encl : 0|16@1+ (0.003418803418803419,0) [0|14] "" Vector__XXX

BO_ 616 LV_FEEDBACK_GPIO_EXTENDER: 2 Vector__XXX
 SG_ feedback_discharge : 9|1@1+ (1,0) [0|1] "" Vector__XXX
 SG_ feedback_frg : 8|1@1+ (1,0) [0|1] "" Vector__XXX
 SG_ feedback_rfe : 7|1@1+ (1,0) [0|1] "" Vector__XXX
 SG_ feedback_autonomous_system_actuation : 6|1@1+ (1,0) [0|1] "" Vector__XXX
 SG_ feedback_hv_fans : 5|1@1+ (1,0) [0|1] "" Vector__XXX
 SG_ feedback_shutdown : 4|1@1+ (1,0) [0|1] "" Vector__XXX
 SG_ feedback_radiators : 3|1@1+ (1,0) [0|1] "" Vector__XXX
 SG_ feedback_pumps : 2|1@1+ (1,0) [0|1] "" Vector__XXX
 SG_ feedback_pcbs : 1|1@1+ (1,0) [0|1] "" Vector__XXX
 SG_ feedback_inverters : 0|1@1+ (1,0) [0|1] "" Vector__XXX

BO_ 56 LV_CAN_FLASH_REQ_TLM: 0 Vector__XXX

BO_ 64 LV_CAN_FLASH_REQ_STEERING_WHEEL: 0 Vector__XXX

BO_ 72 LV_CAN_FLASH_ACK: 0 Vector__XXX

BO_ 624 LV_INVERTER_CONNECTION_STATUS: 1 Vector__XXX
 SG_ status : 0|1@1+ (1,0) [0|1] "" Vector__XXX

BO_ 80 LV_SET_INVERTER_CONNECTION_STATUS: 1 Vector__XXX
 SG_ status : 0|1@1+ (1,0) [0|1] "" Vector__XXX

BO_ 1600 TLM_STATUS: 1 Vector__XXX
 SG_ status : 0|1@1+ (1,0) [0|1] "" Vector__XXX

BO_ 1072 TLM_SET_STATUS: 1 Vector__XXX
 SG_ status : 0|1@1+ (1,0) [0|1] "" Vector__XXX

BO_ 632 HANDCART_STATUS: 1 Vector__XXX
 SG_ connected : 0|1@1+ (1,0) [0|1] "" Vector__XXX

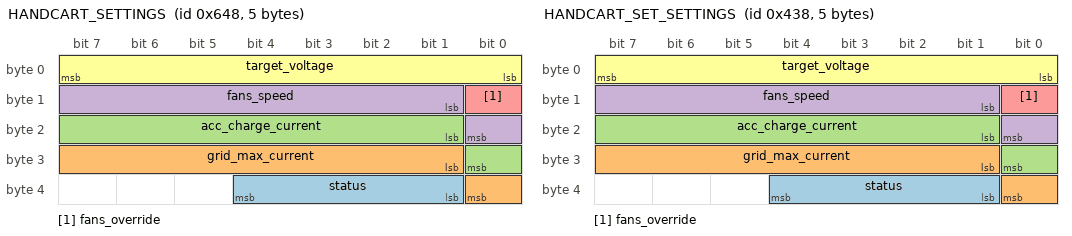
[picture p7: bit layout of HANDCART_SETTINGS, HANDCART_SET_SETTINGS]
BO_ 1608 HANDCART_SETTINGS: 5 Vector__XXX
 SG_ status : 33|4@1+ (1,0) [0|15] "" Vector__XXX
 SG_ grid_max_current : 25|8@1+ (0.058823529411764705,1) [1|16] "" Vector__XXX
 SG_ acc_charge_current : 17|8@1+ (0.058823529411764705,1) [1|16] "" Vector__XXX
 SG_ fans_speed : 9|8@1+ (0.00392156862745098,0) [0|1] "" Vector__XXX
 SG_ fans_override : 8|1@1+ (1,0) [0|1] "" Vector__XXX
 SG_ target_voltage : 0|8@1+ (0.6039215686274509,300) [300|454] "" Vector__XXX

BO_ 1080 HANDCART_SET_SETTINGS: 5 Vector__XXX
 SG_ status : 33|4@1+ (1,0) [0|15] "" Vector__XXX
 SG_ grid_max_current : 25|8@1+ (0.058823529411764705,1) [1|16] "" Vector__XXX
 SG_ acc_charge_current : 17|8@1+ (0.058823529411764705,1) [1|16] "" Vector__XXX
 SG_ fans_speed : 9|8@1+ (0.00392156862745098,0) [0|1] "" Vector__XXX
 SG_ fans_override : 8|1@1+ (1,0) [0|1] "" Vector__XXX
 SG_ target_voltage : 0|8@1+ (0.6039215686274509,300) [300|454] "" Vector__XXX

BO_ 640 ECU_STATUS: 1 Vector__XXX
 SG_ status : 0|4@1+ (1,0) [0|15] "" Vector__XXX

BO_ 88 ECU_SET_STATUS: 1 Vector__XXX
 SG_ status : 0|2@1+ (1,0) [0|3] "" Vector__XXX

BO_ 1088 ECU_INVERTER_STATUS: 1 Vector__XXX
 SG_ rr : 2|2@1+ (1,0) [0|3] "" Vector__XXX
 SG_ rl : 0|2@1+ (1,0) [0|3] "" Vector__XXX

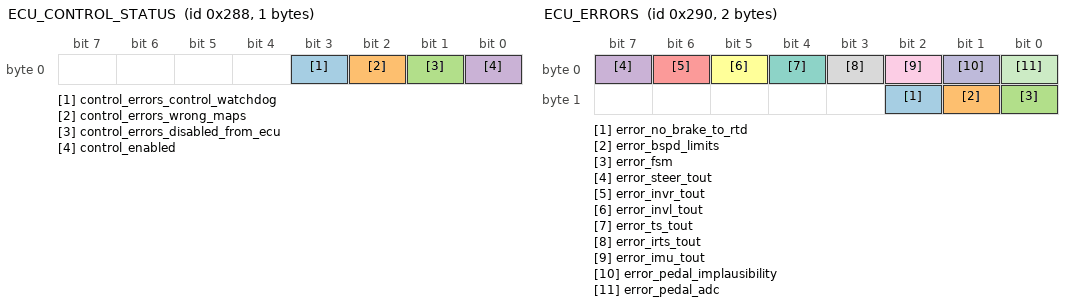
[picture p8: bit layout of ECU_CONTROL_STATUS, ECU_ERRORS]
BO_ 648 ECU_CONTROL_STATUS: 1 Vector__XXX
 SG_ control_errors_control_watchdog : 3|1@1+ (1,0) [0|1] "" Vector__XXX
 SG_ control_errors_wrong_maps : 2|1@1+ (1,0) [0|1] "" Vector__XXX
 SG_ control_errors_disabled_from_ecu : 1|1@1+ (1,0) [0|1] "" Vector__XXX
 SG_ control_enabled : 0|1@1+ (1,0) [0|1] "" Vector__XXX

BO_ 656 ECU_ERRORS: 2 Vector__XXX
 SG_ error_no_brake_to_rtd : 10|1@1+ (1,0) [0|1] "" Vector__XXX
 SG_ error_bspd_limits : 9|1@1+ (1,0) [0|1] "" Vector__XXX
 SG_ error_fsm : 8|1@1+ (1,0) [0|1] "" Vector__XXX
 SG_ error_steer_tout : 7|1@1+ (1,0) [0|1] "" Vector__XXX
 SG_ error_invr_tout : 6|1@1+ (1,0) [0|1] "" Vector__XXX
 SG_ error_invl_tout : 5|1@1+ (1,0) [0|1] "" Vector__XXX
 SG_ error_ts_tout : 4|1@1+ (1,0) [0|1] "" Vector__XXX
 SG_ error_irts_tout : 3|1@1+ (1,0) [0|1] "" Vector__XXX
 SG_ error_imu_tout : 2|1@1+ (1,0) [0|1] "" Vector__XXX
 SG_ error_pedal_implausibility : 1|1@1+ (1,0) [0|1] "" Vector__XXX
 SG_ error_pedal_adc : 0|1@1+ (1,0) [0|1] "" Vector__XXX

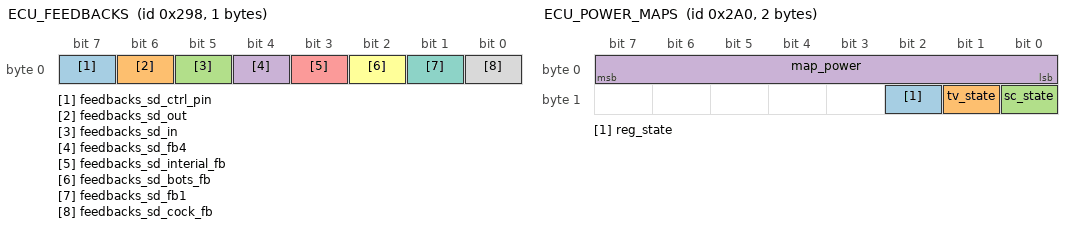
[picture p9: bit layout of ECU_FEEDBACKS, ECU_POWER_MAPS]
BO_ 664 ECU_FEEDBACKS: 1 Vector__XXX
 SG_ feedbacks_sd_ctrl_pin : 7|1@1+ (1,0) [0|1] "" Vector__XXX
 SG_ feedbacks_sd_out : 6|1@1+ (1,0) [0|1] "" Vector__XXX
 SG_ feedbacks_sd_in : 5|1@1+ (1,0) [0|1] "" Vector__XXX
 SG_ feedbacks_sd_fb4 : 4|1@1+ (1,0) [0|1] "" Vector__XXX
 SG_ feedbacks_sd_interial_fb : 3|1@1+ (1,0) [0|1] "" Vector__XXX
 SG_ feedbacks_sd_bots_fb : 2|1@1+ (1,0) [0|1] "" Vector__XXX
 SG_ feedbacks_sd_fb1 : 1|1@1+ (1,0) [0|1] "" Vector__XXX
 SG_ feedbacks_sd_cock_fb : 0|1@1+ (1,0) [0|1] "" Vector__XXX

BO_ 672 ECU_POWER_MAPS: 2 Vector__XXX
 SG_ reg_state : 10|1@1+ (1,0) [0|1] "" Vector__XXX
 SG_ tv_state : 9|1@1+ (1,0) [0|1] "" Vector__XXX
 SG_ sc_state : 8|1@1+ (1,0) [0|1] "" Vector__XXX
 SG_ map_power : 0|8@1+ (0.01,-0.5) [-0.5|1] "" Vector__XXX

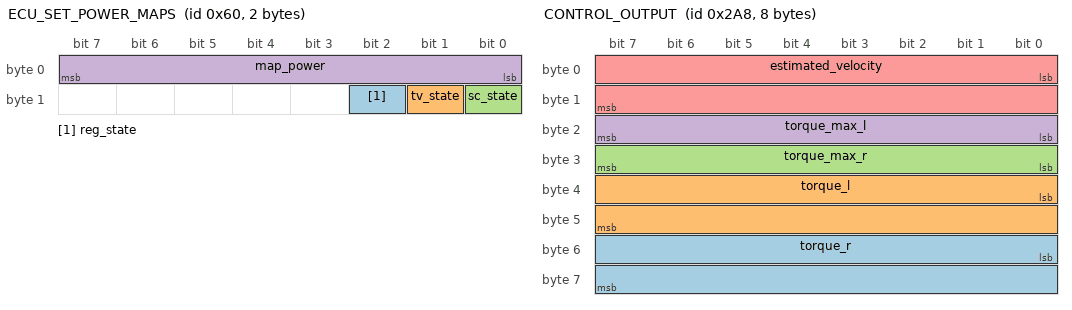
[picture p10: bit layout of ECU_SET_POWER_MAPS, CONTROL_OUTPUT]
BO_ 96 ECU_SET_POWER_MAPS: 2 Vector__XXX
 SG_ reg_state : 10|1@1+ (1,0) [0|1] "" Vector__XXX
 SG_ tv_state : 9|1@1+ (1,0) [0|1] "" Vector__XXX
 SG_ sc_state : 8|1@1+ (1,0) [0|1] "" Vector__XXX
 SG_ map_power : 0|8@1+ (0.01,-0.5) [-0.5|1] "" Vector__XXX

BO_ 1616 ECU_PTT_STATUS: 1 Vector__XXX
 SG_ status : 0|1@1+ (1,0) [0|1] "" Vector__XXX

BO_ 1096 ECU_SET_PTT_STATUS: 1 Vector__XXX
 SG_ status : 0|1@1+ (1,0) [0|1] "" Vector__XXX

BO_ 513 INV_L_REQUEST: 8 Vector__XXX
 SG_ data_7 : 56|8@1+ (1,0) [0|255] "" Vector__XXX
 SG_ data_6 : 48|8@1+ (1,0) [0|255] "" Vector__XXX
 SG_ data_5 : 40|8@1+ (1,0) [0|255] "" Vector__XXX
 SG_ data_4 : 32|8@1+ (1,0) [0|255] "" Vector__XXX
 SG_ data_3 : 24|8@1+ (1,0) [0|255] "" Vector__XXX
 SG_ data_2 : 16|8@1+ (1,0) [0|255] "" Vector__XXX
 SG_ data_1 : 8|8@1+ (1,0) [0|255] "" Vector__XXX
 SG_ data_0 : 0|8@1+ (1,0) [0|255] "" Vector__XXX

BO_ 680 CONTROL_OUTPUT: 8 Vector__XXX
 SG_ torque_r : 48|16@1+ (0.0030518043793392844,-100) [-100|100] "" Vector__XXX
 SG_ torque_l : 32|16@1+ (0.0030518043793392844,-100) [-100|100] "" Vector__XXX
 SG_ torque_max_r : 24|8@1+ (0.7843137254901961,-100) [-100|100] "" Vector__XXX
 SG_ torque_max_l : 16|8@1+ (0.7843137254901961,-100) [-100|100] "" Vector__XXX
 SG_ estimated_velocity : 0|16@1+ (0.000686655985351339,-10) [-10|35] "" Vector__XXX

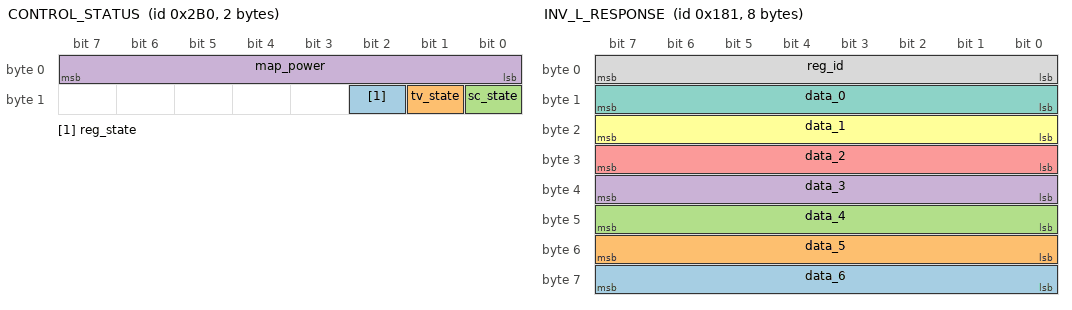
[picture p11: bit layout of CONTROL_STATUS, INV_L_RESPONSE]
BO_ 688 CONTROL_STATUS: 2 Vector__XXX
 SG_ reg_state : 10|1@1+ (1,0) [0|1] "" Vector__XXX
 SG_ tv_state : 9|1@1+ (1,0) [0|1] "" Vector__XXX
 SG_ sc_state : 8|1@1+ (1,0) [0|1] "" Vector__XXX
 SG_ map_power : 0|8@1+ (0.01,-0.5) [-0.5|1] "" Vector__XXX

BO_ 514 INV_R_REQUEST: 8 Vector__XXX
 SG_ data_7 : 56|8@1+ (1,0) [0|255] "" Vector__XXX
 SG_ data_6 : 48|8@1+ (1,0) [0|255] "" Vector__XXX
 SG_ data_5 : 40|8@1+ (1,0) [0|255] "" Vector__XXX
 SG_ data_4 : 32|8@1+ (1,0) [0|255] "" Vector__XXX
 SG_ data_3 : 24|8@1+ (1,0) [0|255] "" Vector__XXX
 SG_ data_2 : 16|8@1+ (1,0) [0|255] "" Vector__XXX
 SG_ data_1 : 8|8@1+ (1,0) [0|255] "" Vector__XXX
 SG_ data_0 : 0|8@1+ (1,0) [0|255] "" Vector__XXX

BO_ 385 INV_L_RESPONSE: 8 Vector__XXX
 SG_ data_6 : 56|8@1+ (1,0) [0|255] "" Vector__XXX
 SG_ data_5 : 48|8@1+ (1,0) [0|255] "" Vector__XXX
 SG_ data_4 : 40|8@1+ (1,0) [0|255] "" Vector__XXX
 SG_ data_3 : 32|8@1+ (1,0) [0|255] "" Vector__XXX
 SG_ data_2 : 24|8@1+ (1,0) [0|255] "" Vector__XXX
 SG_ data_1 : 16|8@1+ (1,0) [0|255] "" Vector__XXX
 SG_ data_0 : 8|8@1+ (1,0) [0|255] "" Vector__XXX
 SG_ reg_id : 0|8@1+ (1,0) [0|255] "" Vector__XXX

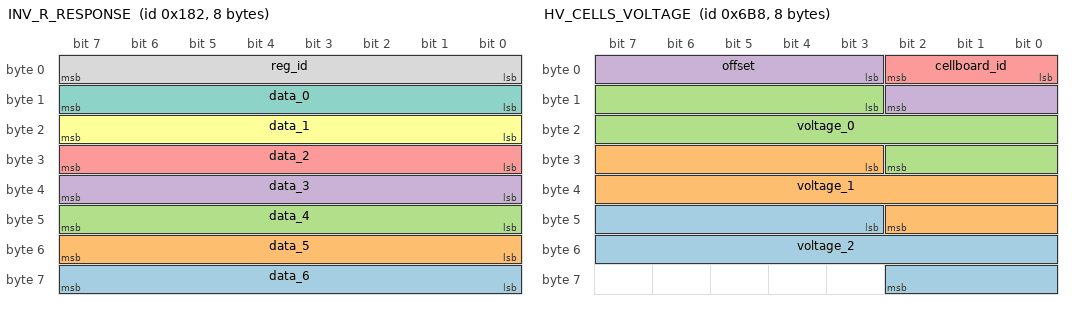
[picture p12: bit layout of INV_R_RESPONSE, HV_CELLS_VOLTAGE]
BO_ 386 INV_R_RESPONSE: 8 Vector__XXX
 SG_ data_6 : 56|8@1+ (1,0) [0|255] "" Vector__XXX
 SG_ data_5 : 48|8@1+ (1,0) [0|255] "" Vector__XXX
 SG_ data_4 : 40|8@1+ (1,0) [0|255] "" Vector__XXX
 SG_ data_3 : 32|8@1+ (1,0) [0|255] "" Vector__XXX
 SG_ data_2 : 24|8@1+ (1,0) [0|255] "" Vector__XXX
 SG_ data_1 : 16|8@1+ (1,0) [0|255] "" Vector__XXX
 SG_ data_0 : 8|8@1+ (1,0) [0|255] "" Vector__XXX
 SG_ reg_id : 0|8@1+ (1,0) [0|255] "" Vector__XXX

BO_ 1624 LV_CURRENT_BATTERY: 2 Vector__XXX
 SG_ lv_current : 0|16@1+ (0.07827788649706457,-20) [-20|20] "" Vector__XXX

BO_ 1632 LV_CURRENT_CHARGER: 2 Vector__XXX
 SG_ charger_current : 0|16@1+ (0.07827788649706457,-20) [-20|20] "" Vector__XXX

BO_ 1640 LV_TOTAL_VOLTAGE: 4 Vector__XXX
 SG_ total : 0|32@1+ (9.918250725748923e-05,0) [0|26] "" Vector__XXX

BO_ 1648 LV_CELLS_VOLTAGE: 7 Vector__XXX
 SG_ voltage_2 : 40|16@1+ (7.629510948348211e-05,0) [0|5] "" Vector__XXX
 SG_ voltage_1 : 24|16@1+ (7.629510948348211e-05,0) [0|5] "" Vector__XXX
 SG_ voltage_0 : 8|16@1+ (7.629510948348211e-05,0) [0|5] "" Vector__XXX
 SG_ start_index : 0|8@1+ (1,0) [0|255] "" Vector__XXX

BO_ 1656 LV_CELLS_VOLTAGE_STATS: 8 Vector__XXX
 SG_ avg : 48|16@1+ (7.629510948348211e-05,0) [0|5] "" Vector__XXX
 SG_ delta : 32|16@1+ (7.629510948348211e-05,0) [0|5] "" Vector__XXX
 SG_ min : 16|16@1+ (7.629510948348211e-05,0) [0|5] "" Vector__XXX
 SG_ max : 0|16@1+ (7.629510948348211e-05,0) [0|5] "" Vector__XXX

BO_ 1664 LV_CELLS_TEMP: 7 Vector__XXX
 SG_ temp_2 : 40|16@1+ (0.0061038881767686015,-20) [-20|80] "" Vector__XXX
 SG_ temp_1 : 24|16@1+ (0.0061038881767686015,-20) [-20|80] "" Vector__XXX
 SG_ temp_0 : 8|16@1+ (0.0061038881767686015,-20) [-20|80] "" Vector__XXX
 SG_ start_index : 0|8@1+ (1,0) [0|255] "" Vector__XXX

BO_ 1672 LV_CELLS_TEMP_STATS: 6 Vector__XXX
 SG_ avg : 32|16@1+ (0.0061038881767686015,-20) [-20|80] "" Vector__XXX
 SG_ min : 16|16@1+ (0.0061038881767686015,-20) [-20|80] "" Vector__XXX
 SG_ max : 0|16@1+ (0.0061038881767686015,-20) [-20|80] "" Vector__XXX

BO_ 1680 HV_CURRENT: 4 Vector__XXX
 SG_ current : 0|32@1+ (0.0006637598562616587,-39) [-39|135] "" Vector__XXX

BO_ 1688 HV_POWER: 2 Vector__XXX
 SG_ power : 0|16@1+ (0.0030518043793392844,-100) [-100|100] "" Vector__XXX

BO_ 1696 HV_ENERGY: 2 Vector__XXX
 SG_ energy : 0|16@1+ (0.10681315327687495,0) [0|7000] "" Vector__XXX

BO_ 1704 HV_SOC: 1 Vector__XXX
 SG_ soc : 0|8@1+ (0.00392156862745098,0) [0|1] "" Vector__XXX

BO_ 1712 HV_TOTAL_VOLTAGE: 6 Vector__XXX
 SG_ bus : 32|16@1+ (0.9001956947162426,0) [0|460] "" Vector__XXX
 SG_ sum_cell : 16|16@1+ (0.9001956947162426,0) [0|460] "" Vector__XXX
 SG_ pack : 0|16@1+ (0.9001956947162426,0) [0|460] "" Vector__XXX

BO_ 1720 HV_CELLS_VOLTAGE: 8 Vector__XXX
 SG_ voltage_2 : 43|16@1+ (7.629510948348211e-05,0) [0|5] "" Vector__XXX
 SG_ voltage_1 : 27|16@1+ (7.629510948348211e-05,0) [0|5] "" Vector__XXX
 SG_ voltage_0 : 11|16@1+ (7.629510948348211e-05,0) [0|5] "" Vector__XXX
 SG_ offset : 3|8@1+ (1,0) [0|21] "" Vector__XXX
 SG_ cellboard_id : 0|3@1+ (1,0) [0|7] "" Vector__XXX

BO_ 1728 HV_CELLS_VOLTAGE_STATS: 8 Vector__XXX
 SG_ avg : 48|16@1+ (7.629510948348211e-05,0) [0|5] "" Vector__XXX
 SG_ delta : 32|16@1+ (0.007019150072480354,0) [0|460] "" Vector__XXX
 SG_ min : 16|16@1+ (7.629510948348211e-05,0) [0|5] "" Vector__XXX
 SG_ max : 0|16@1+ (7.629510948348211e-05,0) [0|5] "" Vector__XXX

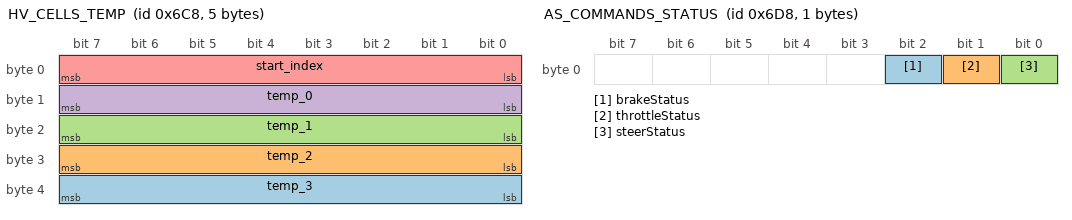
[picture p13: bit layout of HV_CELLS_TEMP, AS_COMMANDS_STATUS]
BO_ 1736 HV_CELLS_TEMP: 5 Vector__XXX
 SG_ temp_3 : 32|8@1+ (0.39215686274509803,-20) [-20|80] "" Vector__XXX
 SG_ temp_2 : 24|8@1+ (0.39215686274509803,-20) [-20|80] "" Vector__XXX
 SG_ temp_1 : 16|8@1+ (0.39215686274509803,-20) [-20|80] "" Vector__XXX
 SG_ temp_0 : 8|8@1+ (0.39215686274509803,-20) [-20|80] "" Vector__XXX
 SG_ start_index : 0|8@1+ (1,0) [0|255] "" Vector__XXX

BO_ 1744 HV_CELLS_TEMP_STATS: 6 Vector__XXX
 SG_ avg : 32|16@1+ (0.0061038881767686015,-20) [-20|80] "" Vector__XXX
 SG_ min : 16|16@1+ (0.0061038881767686015,-20) [-20|80] "" Vector__XXX
 SG_ max : 0|16@1+ (0.0061038881767686015,-20) [-20|80] "" Vector__XXX

BO_ 1752 AS_COMMANDS_STATUS: 1 Vector__XXX
 SG_ brakeStatus : 2|1@1+ (1,0) [0|1] "" Vector__XXX
 SG_ throttleStatus : 1|1@1+ (1,0) [0|1] "" Vector__XXX
 SG_ steerStatus : 0|1@1+ (1,0) [0|1] "" Vector__XXX

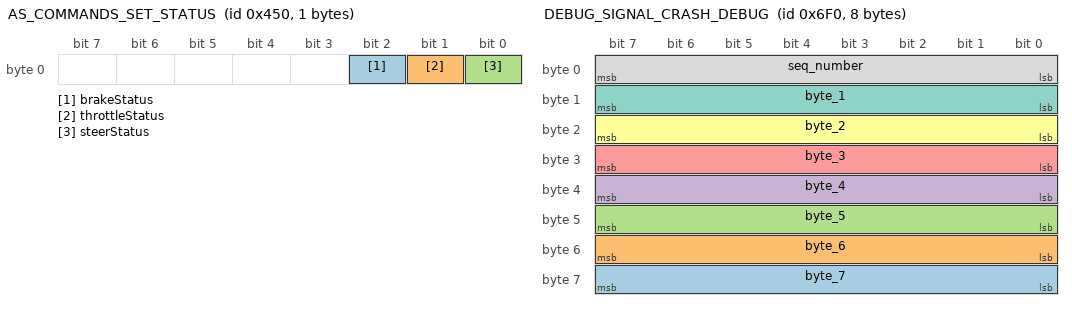
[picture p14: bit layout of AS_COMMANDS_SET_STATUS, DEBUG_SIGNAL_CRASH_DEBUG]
BO_ 1104 AS_COMMANDS_SET_STATUS: 1 Vector__XXX
 SG_ brakeStatus : 2|1@1+ (1,0) [0|1] "" Vector__XXX
 SG_ throttleStatus : 1|1@1+ (1,0) [0|1] "" Vector__XXX
 SG_ steerStatus : 0|1@1+ (1,0) [0|1] "" Vector__XXX

BO_ 1760 AS_COMMANDS_SET_VALUE: 6 Vector__XXX
 SG_ brake : 32|16@1+ (1.5259021896696422e-05,-1) [-1|0] "" Vector__XXX
 SG_ throttle : 16|16@1+ (1.5259021896696422e-05,0) [0|1] "" Vector__XXX
 SG_ steerAngle : 0|16@1+ (0.005493247882810712,-180) [-180|180] "" Vector__XXX

BO_ 1768 ECU_STEER_ACTUATOR_CURRENT: 1 Vector__XXX
 SG_ current : 0|8@1+ (0.19607843137254902,-25) [-25|25] "" Vector__XXX

BO_ 1776 DEBUG_SIGNAL_CRASH_DEBUG: 8 Vector__XXX
 SG_ byte_7 : 56|8@1+ (1,0) [0|255] "" Vector__XXX
 SG_ byte_6 : 48|8@1+ (1,0) [0|255] "" Vector__XXX
 SG_ byte_5 : 40|8@1+ (1,0) [0|255] "" Vector__XXX
 SG_ byte_4 : 32|8@1+ (1,0) [0|255] "" Vector__XXX
 SG_ byte_3 : 24|8@1+ (1,0) [0|255] "" Vector__XXX
 SG_ byte_2 : 16|8@1+ (1,0) [0|255] "" Vector__XXX
 SG_ byte_1 : 8|8@1+ (1,0) [0|255] "" Vector__XXX
 SG_ seq_number : 0|8@1+ (1,0) [0|255] "" Vector__XXX

BO_ 1784 DEBUG_SIGNAL_CRASH_DEBUG_ACK: 1 Vector__XXX
 SG_ seq_number : 0|8@1+ (1,0) [0|255] "" Vector__XXX

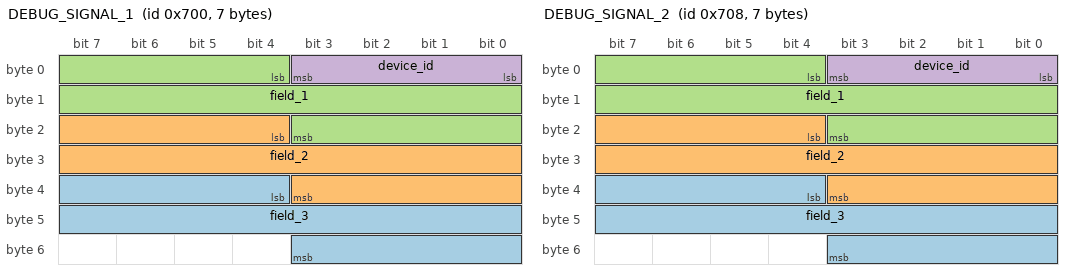
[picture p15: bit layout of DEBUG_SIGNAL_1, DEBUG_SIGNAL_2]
BO_ 1792 DEBUG_SIGNAL_1: 7 Vector__XXX
 SG_ field_3 : 36|16@1+ (3.0518043793392844e-05,-1) [-1|1] "" Vector__XXX
 SG_ field_2 : 20|16@1+ (3.0518043793392844e-05,-1) [-1|1] "" Vector__XXX
 SG_ field_1 : 4|16@1+ (3.0518043793392844e-05,-1) [-1|1] "" Vector__XXX
 SG_ device_id : 0|4@1+ (1,0) [0|15] "" Vector__XXX

BO_ 1800 DEBUG_SIGNAL_2: 7 Vector__XXX
 SG_ field_3 : 36|16@1+ (3.0518043793392844e-05,-1) [-1|1] "" Vector__XXX
 SG_ field_2 : 20|16@1+ (3.0518043793392844e-05,-1) [-1|1] "" Vector__XXX
 SG_ field_1 : 4|16@1+ (3.0518043793392844e-05,-1) [-1|1] "" Vector__XXX
 SG_ device_id : 0|4@1+ (1,0) [0|15] "" Vector__XXX

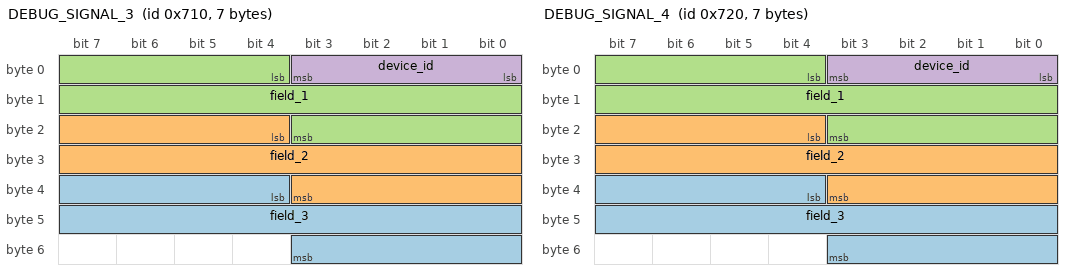
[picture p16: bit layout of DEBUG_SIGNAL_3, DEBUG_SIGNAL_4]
BO_ 1808 DEBUG_SIGNAL_3: 7 Vector__XXX
 SG_ field_3 : 36|16@1+ (3.0518043793392844e-05,-1) [-1|1] "" Vector__XXX
 SG_ field_2 : 20|16@1+ (3.0518043793392844e-05,-1) [-1|1] "" Vector__XXX
 SG_ field_1 : 4|16@1+ (3.0518043793392844e-05,-1) [-1|1] "" Vector__XXX
 SG_ device_id : 0|4@1+ (1,0) [0|15] "" Vector__XXX

BO_ 1824 DEBUG_SIGNAL_4: 7 Vector__XXX
 SG_ field_3 : 36|16@1+ (3.0518043793392844e-05,-1) [-1|1] "" Vector__XXX
 SG_ field_2 : 20|16@1+ (3.0518043793392844e-05,-1) [-1|1] "" Vector__XXX
 SG_ field_1 : 4|16@1+ (3.0518043793392844e-05,-1) [-1|1] "" Vector__XXX
 SG_ device_id : 0|4@1+ (1,0) [0|15] "" Vector__XXX

BO_ 50 HV_FLASH_REQUEST: 1 Vector__XXX
 SG_ cellboard_id : 1|3@1+ (1,0) [0|7] "" Vector__XXX
 SG_ mainboard : 0|1@1+ (1,0) [0|1] "" Vector__XXX

BO_ 51 HV_FLASH_RESPONSE: 1 Vector__XXX
 SG_ ready : 0|1@1+ (1,0) [0|1] "" Vector__XXX

BO_ 1112 HV_TS_VOLTAGE: 6 Vector__XXX
 SG_ cells_sum : 32|16@1+ (0.009231708247501335,0) [0|605] "" Vector__XXX
 SG_ pack : 16|16@1+ (0.009231708247501335,0) [0|605] "" Vector__XXX
 SG_ ts : 0|16@1+ (0.009231708247501335,0) [0|605] "" Vector__XXX

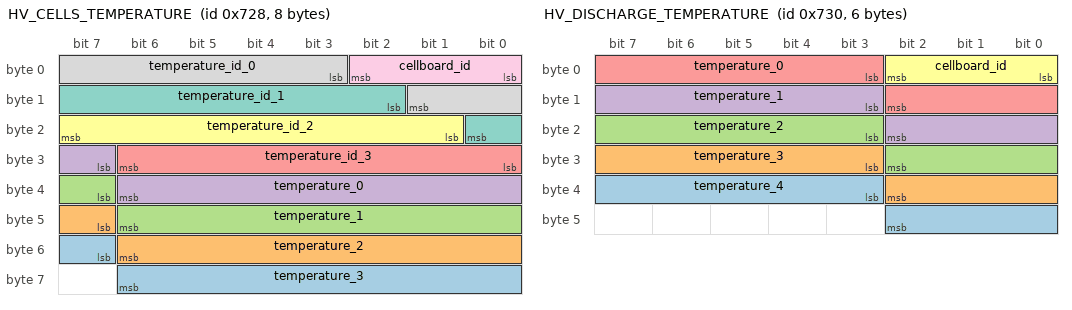
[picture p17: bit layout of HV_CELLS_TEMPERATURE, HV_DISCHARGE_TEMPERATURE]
BO_ 1832 HV_CELLS_TEMPERATURE: 8 Vector__XXX
 SG_ temperature_3 : 55|8@1+ (0.49019607843137253,-25.0) [-25.0|100.0] "" Vector__XXX
 SG_ temperature_2 : 47|8@1+ (0.49019607843137253,-25.0) [-25.0|100.0] "" Vector__XXX
 SG_ temperature_1 : 39|8@1+ (0.49019607843137253,-25.0) [-25.0|100.0] "" Vector__XXX
 SG_ temperature_0 : 31|8@1+ (0.49019607843137253,-25.0) [-25.0|100.0] "" Vector__XXX
 SG_ temperature_id_3 : 24|7@1+ (1,1) [1|75] "" Vector__XXX
 SG_ temperature_id_2 : 17|7@1+ (1,1) [1|75] "" Vector__XXX
 SG_ temperature_id_1 : 10|7@1+ (1,1) [1|75] "" Vector__XXX
 SG_ temperature_id_0 : 3|7@1+ (1,1) [1|75] "" Vector__XXX
 SG_ cellboard_id : 0|3@1+ (1,0) [0|7] "" Vector__XXX

BO_ 1840 HV_DISCHARGE_TEMPERATURE: 6 Vector__XXX
 SG_ temperature_4 : 35|8@1+ (0.49019607843137253,-25.0) [-25.0|100.0] "" Vector__XXX
 SG_ temperature_3 : 27|8@1+ (0.49019607843137253,-25.0) [-25.0|100.0] "" Vector__XXX
 SG_ temperature_2 : 19|8@1+ (0.49019607843137253,-25.0) [-25.0|100.0] "" Vector__XXX
 SG_ temperature_1 : 11|8@1+ (0.49019607843137253,-25.0) [-25.0|100.0] "" Vector__XXX
 SG_ temperature_0 : 3|8@1+ (0.49019607843137253,-25.0) [-25.0|100.0] "" Vector__XXX
 SG_ cellboard_id : 0|3@1+ (1,0) [0|7] "" Vector__XXX

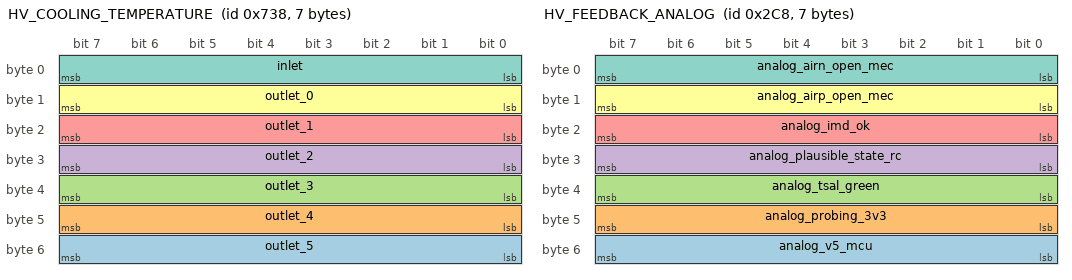
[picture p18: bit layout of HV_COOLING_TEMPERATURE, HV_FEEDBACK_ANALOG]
BO_ 1848 HV_COOLING_TEMPERATURE: 7 Vector__XXX
 SG_ outlet_5 : 48|8@1+ (0.49019607843137253,-25.0) [-25.0|100.0] "" Vector__XXX
 SG_ outlet_4 : 40|8@1+ (0.49019607843137253,-25.0) [-25.0|100.0] "" Vector__XXX
 SG_ outlet_3 : 32|8@1+ (0.49019607843137253,-25.0) [-25.0|100.0] "" Vector__XXX
 SG_ outlet_2 : 24|8@1+ (0.49019607843137253,-25.0) [-25.0|100.0] "" Vector__XXX
 SG_ outlet_1 : 16|8@1+ (0.49019607843137253,-25.0) [-25.0|100.0] "" Vector__XXX
 SG_ outlet_0 : 8|8@1+ (0.49019607843137253,-25.0) [-25.0|100.0] "" Vector__XXX
 SG_ inlet : 0|8@1+ (0.49019607843137253,-25.0) [-25.0|100.0] "" Vector__XXX

BO_ 256 CHARGER_1: 8 Vector__XXX
 SG_ data_7 : 56|8@1+ (1,0) [0|255] "" Vector__XXX
 SG_ data_6 : 48|8@1+ (1,0) [0|255] "" Vector__XXX
 SG_ data_5 : 40|8@1+ (1,0) [0|255] "" Vector__XXX
 SG_ data_4 : 32|8@1+ (1,0) [0|255] "" Vector__XXX
 SG_ data_3 : 24|8@1+ (1,0) [0|255] "" Vector__XXX
 SG_ data_2 : 16|8@1+ (1,0) [0|255] "" Vector__XXX
 SG_ data_1 : 8|8@1+ (1,0) [0|255] "" Vector__XXX
 SG_ data_0 : 0|8@1+ (1,0) [0|255] "" Vector__XXX

BO_ 272 CHARGER_2: 8 Vector__XXX
 SG_ data_7 : 56|8@1+ (1,0) [0|255] "" Vector__XXX
 SG_ data_6 : 48|8@1+ (1,0) [0|255] "" Vector__XXX
 SG_ data_5 : 40|8@1+ (1,0) [0|255] "" Vector__XXX
 SG_ data_4 : 32|8@1+ (1,0) [0|255] "" Vector__XXX
 SG_ data_3 : 24|8@1+ (1,0) [0|255] "" Vector__XXX
 SG_ data_2 : 16|8@1+ (1,0) [0|255] "" Vector__XXX
 SG_ data_1 : 8|8@1+ (1,0) [0|255] "" Vector__XXX
 SG_ data_0 : 0|8@1+ (1,0) [0|255] "" Vector__XXX

BO_ 288 CHARGER_3: 8 Vector__XXX
 SG_ data_7 : 56|8@1+ (1,0) [0|255] "" Vector__XXX
 SG_ data_6 : 48|8@1+ (1,0) [0|255] "" Vector__XXX
 SG_ data_5 : 40|8@1+ (1,0) [0|255] "" Vector__XXX
 SG_ data_4 : 32|8@1+ (1,0) [0|255] "" Vector__XXX
 SG_ data_3 : 24|8@1+ (1,0) [0|255] "" Vector__XXX
 SG_ data_2 : 16|8@1+ (1,0) [0|255] "" Vector__XXX
 SG_ data_1 : 8|8@1+ (1,0) [0|255] "" Vector__XXX
 SG_ data_0 : 0|8@1+ (1,0) [0|255] "" Vector__XXX

BO_ 304 CHARGER_4: 8 Vector__XXX
 SG_ data_7 : 56|8@1+ (1,0) [0|255] "" Vector__XXX
 SG_ data_6 : 48|8@1+ (1,0) [0|255] "" Vector__XXX
 SG_ data_5 : 40|8@1+ (1,0) [0|255] "" Vector__XXX
 SG_ data_4 : 32|8@1+ (1,0) [0|255] "" Vector__XXX
 SG_ data_3 : 24|8@1+ (1,0) [0|255] "" Vector__XXX
 SG_ data_2 : 16|8@1+ (1,0) [0|255] "" Vector__XXX
 SG_ data_1 : 8|8@1+ (1,0) [0|255] "" Vector__XXX
 SG_ data_0 : 0|8@1+ (1,0) [0|255] "" Vector__XXX

BO_ 320 CHARGER_5: 8 Vector__XXX
 SG_ data_7 : 56|8@1+ (1,0) [0|255] "" Vector__XXX
 SG_ data_6 : 48|8@1+ (1,0) [0|255] "" Vector__XXX
 SG_ data_5 : 40|8@1+ (1,0) [0|255] "" Vector__XXX
 SG_ data_4 : 32|8@1+ (1,0) [0|255] "" Vector__XXX
 SG_ data_3 : 24|8@1+ (1,0) [0|255] "" Vector__XXX
 SG_ data_2 : 16|8@1+ (1,0) [0|255] "" Vector__XXX
 SG_ data_1 : 8|8@1+ (1,0) [0|255] "" Vector__XXX
 SG_ data_0 : 0|8@1+ (1,0) [0|255] "" Vector__XXX

BO_ 336 CHARGER_6: 8 Vector__XXX
 SG_ data_7 : 56|8@1+ (1,0) [0|255] "" Vector__XXX
 SG_ data_6 : 48|8@1+ (1,0) [0|255] "" Vector__XXX
 SG_ data_5 : 40|8@1+ (1,0) [0|255] "" Vector__XXX
 SG_ data_4 : 32|8@1+ (1,0) [0|255] "" Vector__XXX
 SG_ data_3 : 24|8@1+ (1,0) [0|255] "" Vector__XXX
 SG_ data_2 : 16|8@1+ (1,0) [0|255] "" Vector__XXX
 SG_ data_1 : 8|8@1+ (1,0) [0|255] "" Vector__XXX
 SG_ data_0 : 0|8@1+ (1,0) [0|255] "" Vector__XXX

BO_ 344 CHARGER_7: 8 Vector__XXX
 SG_ data_7 : 56|8@1+ (1,0) [0|255] "" Vector__XXX
 SG_ data_6 : 48|8@1+ (1,0) [0|255] "" Vector__XXX
 SG_ data_5 : 40|8@1+ (1,0) [0|255] "" Vector__XXX
 SG_ data_4 : 32|8@1+ (1,0) [0|255] "" Vector__XXX
 SG_ data_3 : 24|8@1+ (1,0) [0|255] "" Vector__XXX
 SG_ data_2 : 16|8@1+ (1,0) [0|255] "" Vector__XXX
 SG_ data_1 : 8|8@1+ (1,0) [0|255] "" Vector__XXX
 SG_ data_0 : 0|8@1+ (1,0) [0|255] "" Vector__XXX

BO_ 352 CHARGER_8: 8 Vector__XXX
 SG_ data_7 : 56|8@1+ (1,0) [0|255] "" Vector__XXX
 SG_ data_6 : 48|8@1+ (1,0) [0|255] "" Vector__XXX
 SG_ data_5 : 40|8@1+ (1,0) [0|255] "" Vector__XXX
 SG_ data_4 : 32|8@1+ (1,0) [0|255] "" Vector__XXX
 SG_ data_3 : 24|8@1+ (1,0) [0|255] "" Vector__XXX
 SG_ data_2 : 16|8@1+ (1,0) [0|255] "" Vector__XXX
 SG_ data_1 : 8|8@1+ (1,0) [0|255] "" Vector__XXX
 SG_ data_0 : 0|8@1+ (1,0) [0|255] "" Vector__XXX

BO_ 368 CHARGER_9: 8 Vector__XXX
 SG_ data_7 : 56|8@1+ (1,0) [0|255] "" Vector__XXX
 SG_ data_6 : 48|8@1+ (1,0) [0|255] "" Vector__XXX
 SG_ data_5 : 40|8@1+ (1,0) [0|255] "" Vector__XXX
 SG_ data_4 : 32|8@1+ (1,0) [0|255] "" Vector__XXX
 SG_ data_3 : 24|8@1+ (1,0) [0|255] "" Vector__XXX
 SG_ data_2 : 16|8@1+ (1,0) [0|255] "" Vector__XXX
 SG_ data_1 : 8|8@1+ (1,0) [0|255] "" Vector__XXX
 SG_ data_0 : 0|8@1+ (1,0) [0|255] "" Vector__XXX

BO_ 384 CHARGER_10: 8 Vector__XXX
 SG_ data_7 : 56|8@1+ (1,0) [0|255] "" Vector__XXX
 SG_ data_6 : 48|8@1+ (1,0) [0|255] "" Vector__XXX
 SG_ data_5 : 40|8@1+ (1,0) [0|255] "" Vector__XXX
 SG_ data_4 : 32|8@1+ (1,0) [0|255] "" Vector__XXX
 SG_ data_3 : 24|8@1+ (1,0) [0|255] "" Vector__XXX
 SG_ data_2 : 16|8@1+ (1,0) [0|255] "" Vector__XXX
 SG_ data_1 : 8|8@1+ (1,0) [0|255] "" Vector__XXX
 SG_ data_0 : 0|8@1+ (1,0) [0|255] "" Vector__XXX

BO_ 392 CHARGER_11: 8 Vector__XXX
 SG_ data_7 : 56|8@1+ (1,0) [0|255] "" Vector__XXX
 SG_ data_6 : 48|8@1+ (1,0) [0|255] "" Vector__XXX
 SG_ data_5 : 40|8@1+ (1,0) [0|255] "" Vector__XXX
 SG_ data_4 : 32|8@1+ (1,0) [0|255] "" Vector__XXX
 SG_ data_3 : 24|8@1+ (1,0) [0|255] "" Vector__XXX
 SG_ data_2 : 16|8@1+ (1,0) [0|255] "" Vector__XXX
 SG_ data_1 : 8|8@1+ (1,0) [0|255] "" Vector__XXX
 SG_ data_0 : 0|8@1+ (1,0) [0|255] "" Vector__XXX

BO_ 400 CHARGER_12: 8 Vector__XXX
 SG_ data_7 : 56|8@1+ (1,0) [0|255] "" Vector__XXX
 SG_ data_6 : 48|8@1+ (1,0) [0|255] "" Vector__XXX
 SG_ data_5 : 40|8@1+ (1,0) [0|255] "" Vector__XXX
 SG_ data_4 : 32|8@1+ (1,0) [0|255] "" Vector__XXX
 SG_ data_3 : 24|8@1+ (1,0) [0|255] "" Vector__XXX
 SG_ data_2 : 16|8@1+ (1,0) [0|255] "" Vector__XXX
 SG_ data_1 : 8|8@1+ (1,0) [0|255] "" Vector__XXX
 SG_ data_0 : 0|8@1+ (1,0) [0|255] "" Vector__XXX

BO_ 408 CHARGER_13: 8 Vector__XXX
 SG_ data_7 : 56|8@1+ (1,0) [0|255] "" Vector__XXX
 SG_ data_6 : 48|8@1+ (1,0) [0|255] "" Vector__XXX
 SG_ data_5 : 40|8@1+ (1,0) [0|255] "" Vector__XXX
 SG_ data_4 : 32|8@1+ (1,0) [0|255] "" Vector__XXX
 SG_ data_3 : 24|8@1+ (1,0) [0|255] "" Vector__XXX
 SG_ data_2 : 16|8@1+ (1,0) [0|255] "" Vector__XXX
 SG_ data_1 : 8|8@1+ (1,0) [0|255] "" Vector__XXX
 SG_ data_0 : 0|8@1+ (1,0) [0|255] "" Vector__XXX

BO_ 416 CHARGER_14: 8 Vector__XXX
 SG_ data_7 : 56|8@1+ (1,0) [0|255] "" Vector__XXX
 SG_ data_6 : 48|8@1+ (1,0) [0|255] "" Vector__XXX
 SG_ data_5 : 40|8@1+ (1,0) [0|255] "" Vector__XXX
 SG_ data_4 : 32|8@1+ (1,0) [0|255] "" Vector__XXX
 SG_ data_3 : 24|8@1+ (1,0) [0|255] "" Vector__XXX
 SG_ data_2 : 16|8@1+ (1,0) [0|255] "" Vector__XXX
 SG_ data_1 : 8|8@1+ (1,0) [0|255] "" Vector__XXX
 SG_ data_0 : 0|8@1+ (1,0) [0|255] "" Vector__XXX

BO_ 432 CHARGER_15: 8 Vector__XXX
 SG_ data_7 : 56|8@1+ (1,0) [0|255] "" Vector__XXX
 SG_ data_6 : 48|8@1+ (1,0) [0|255] "" Vector__XXX
 SG_ data_5 : 40|8@1+ (1,0) [0|255] "" Vector__XXX
 SG_ data_4 : 32|8@1+ (1,0) [0|255] "" Vector__XXX
 SG_ data_3 : 24|8@1+ (1,0) [0|255] "" Vector__XXX
 SG_ data_2 : 16|8@1+ (1,0) [0|255] "" Vector__XXX
 SG_ data_1 : 8|8@1+ (1,0) [0|255] "" Vector__XXX
 SG_ data_0 : 0|8@1+ (1,0) [0|255] "" Vector__XXX

BO_ 448 CHARGER_16: 8 Vector__XXX
 SG_ data_7 : 56|8@1+ (1,0) [0|255] "" Vector__XXX
 SG_ data_6 : 48|8@1+ (1,0) [0|255] "" Vector__XXX
 SG_ data_5 : 40|8@1+ (1,0) [0|255] "" Vector__XXX
 SG_ data_4 : 32|8@1+ (1,0) [0|255] "" Vector__XXX
 SG_ data_3 : 24|8@1+ (1,0) [0|255] "" Vector__XXX
 SG_ data_2 : 16|8@1+ (1,0) [0|255] "" Vector__XXX
 SG_ data_1 : 8|8@1+ (1,0) [0|255] "" Vector__XXX
 SG_ data_0 : 0|8@1+ (1,0) [0|255] "" Vector__XXX

BO_ 464 CHARGER_17: 8 Vector__XXX
 SG_ data_7 : 56|8@1+ (1,0) [0|255] "" Vector__XXX
 SG_ data_6 : 48|8@1+ (1,0) [0|255] "" Vector__XXX
 SG_ data_5 : 40|8@1+ (1,0) [0|255] "" Vector__XXX
 SG_ data_4 : 32|8@1+ (1,0) [0|255] "" Vector__XXX
 SG_ data_3 : 24|8@1+ (1,0) [0|255] "" Vector__XXX
 SG_ data_2 : 16|8@1+ (1,0) [0|255] "" Vector__XXX
 SG_ data_1 : 8|8@1+ (1,0) [0|255] "" Vector__XXX
 SG_ data_0 : 0|8@1+ (1,0) [0|255] "" Vector__XXX

BO_ 480 CHARGER_18: 8 Vector__XXX
 SG_ data_7 : 56|8@1+ (1,0) [0|255] "" Vector__XXX
 SG_ data_6 : 48|8@1+ (1,0) [0|255] "" Vector__XXX
 SG_ data_5 : 40|8@1+ (1,0) [0|255] "" Vector__XXX
 SG_ data_4 : 32|8@1+ (1,0) [0|255] "" Vector__XXX
 SG_ data_3 : 24|8@1+ (1,0) [0|255] "" Vector__XXX
 SG_ data_2 : 16|8@1+ (1,0) [0|255] "" Vector__XXX
 SG_ data_1 : 8|8@1+ (1,0) [0|255] "" Vector__XXX
 SG_ data_0 : 0|8@1+ (1,0) [0|255] "" Vector__XXX

BO_ 496 CHARGER_19: 8 Vector__XXX
 SG_ data_7 : 56|8@1+ (1,0) [0|255] "" Vector__XXX
 SG_ data_6 : 48|8@1+ (1,0) [0|255] "" Vector__XXX
 SG_ data_5 : 40|8@1+ (1,0) [0|255] "" Vector__XXX
 SG_ data_4 : 32|8@1+ (1,0) [0|255] "" Vector__XXX
 SG_ data_3 : 24|8@1+ (1,0) [0|255] "" Vector__XXX
 SG_ data_2 : 16|8@1+ (1,0) [0|255] "" Vector__XXX
 SG_ data_1 : 8|8@1+ (1,0) [0|255] "" Vector__XXX
 SG_ data_0 : 0|8@1+ (1,0) [0|255] "" Vector__XXX

BO_ 696 HV_FEEDBACK_DIGITAL: 3 Vector__XXX
 SG_ digital_not_ext_fault_latched : 16|1@1+ (1,0) [0|1] "" Vector__XXX
 SG_ digital_not_imd_fault_latched : 15|1@1+ (1,0) [0|1] "" Vector__XXX
 SG_ digital_not_bms_fault_latched : 14|1@1+ (1,0) [0|1] "" Vector__XXX
 SG_ digital_plausible_state_latched : 13|1@1+ (1,0) [0|1] "" Vector__XXX
 SG_ digital_not_latch_reset : 12|1@1+ (1,0) [0|1] "" Vector__XXX
 SG_ digital_indicator_connected : 11|1@1+ (1,0) [0|1] "" Vector__XXX
 SG_ digital_not_imd_fault_cockpit_led : 10|1@1+ (1,0) [0|1] "" Vector__XXX
 SG_ digital_not_bms_fault_cockpit_led : 9|1@1+ (1,0) [0|1] "" Vector__XXX
 SG_ digital_plausible_state : 8|1@1+ (1,0) [0|1] "" Vector__XXX
 SG_ digital_plausible_state_persisted : 7|1@1+ (1,0) [0|1] "" Vector__XXX
 SG_ digital_ts_less_than_60v : 6|1@1+ (1,0) [0|1] "" Vector__XXX
 SG_ digital_precharge_open_mec : 5|1@1+ (1,0) [0|1] "" Vector__XXX
 SG_ digital_precharge_open_com : 4|1@1+ (1,0) [0|1] "" Vector__XXX
 SG_ digital_sd_bms_fb : 3|1@1+ (1,0) [0|1] "" Vector__XXX
 SG_ digital_sd_imd_fb : 2|1@1+ (1,0) [0|1] "" Vector__XXX
 SG_ digital_airp_open_com : 1|1@1+ (1,0) [0|1] "" Vector__XXX
 SG_ digital_airn_open_com : 0|1@1+ (1,0) [0|1] "" Vector__XXX

BO_ 712 HV_FEEDBACK_ANALOG: 7 Vector__XXX
 SG_ analog_v5_mcu : 48|8@1+ (0.0196078431372549,0) [0|5] "" Vector__XXX
 SG_ analog_probing_3v3 : 40|8@1+ (0.012941176470588235,0) [0|3.3] "" Vector__XXX
 SG_ analog_tsal_green : 32|8@1+ (0.012941176470588235,0) [0|3.3] "" Vector__XXX
 SG_ analog_plausible_state_rc : 24|8@1+ (0.012941176470588235,0) [0|3.3] "" Vector__XXX
 SG_ analog_imd_ok : 16|8@1+ (0.012941176470588235,0) [0|3.3] "" Vector__XXX
 SG_ analog_airp_open_mec : 8|8@1+ (0.012941176470588235,0) [0|3.3] "" Vector__XXX
 SG_ analog_airn_open_mec : 0|8@1+ (0.012941176470588235,0) [0|3.3] "" Vector__XXX

BO_ 720 HV_FEEDBACK_ANALOG_SD: 6 Vector__XXX
 SG_ sd_end : 32|16@1+ (0.0007324665812122322,0) [0|12] "" Vector__XXX
 SG_ sd_in : 16|16@1+ (0.0007324665812122322,0) [0|12] "" Vector__XXX
 SG_ sd_out : 0|16@1+ (0.0007324665812122322,0) [0|12] "" Vector__XXX

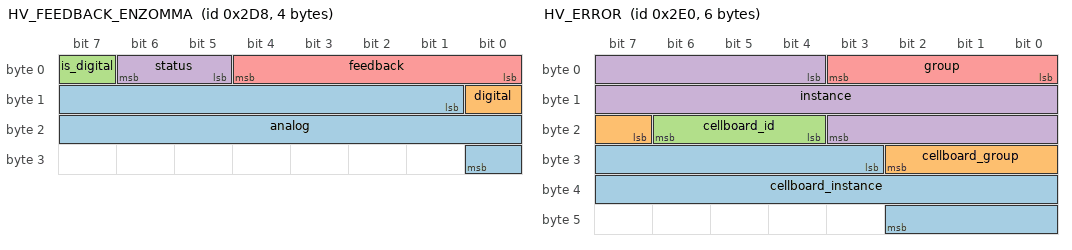
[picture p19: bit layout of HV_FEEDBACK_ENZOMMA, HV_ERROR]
BO_ 728 HV_FEEDBACK_ENZOMMA: 4 Vector__XXX
 SG_ analog : 9|16@1+ (5.035477225909819e-05,0) [0|3.3] "" Vector__XXX
 SG_ digital : 8|1@1+ (1,0) [0|1] "" Vector__XXX
 SG_ is_digital : 7|1@1+ (1,0) [0|1] "" Vector__XXX
 SG_ status : 5|2@1+ (1,0) [0|3] "" Vector__XXX
 SG_ feedback : 0|5@1+ (1,0) [0|31] "" Vector__XXX

BO_ 736 HV_ERROR: 6 Vector__XXX
 SG_ cellboard_instance : 27|16@1+ (1,0) [0|65535] "" Vector__XXX
 SG_ cellboard_group : 23|4@1+ (1,0) [0|15] "" Vector__XXX
 SG_ cellboard_id : 20|3@1+ (1,0) [0|7] "" Vector__XXX
 SG_ instance : 4|16@1+ (1,0) [0|65535] "" Vector__XXX
 SG_ group : 0|4@1+ (1,0) [0|15] "" Vector__XXX

CM_ SG_ 1818 LAD_D_ParamRp "Diag responded data to host";
CM_ SG_ 1816 LAD_D_ParamRq "Diag requested data from host";
CM_ SG_ 1556 NLG5_W_SC_M "Save-Charging-Mode reduces primary current to 3.95 A as long as one of the four internal temperature sensors indicates -18° C or less.
";
CM_ SG_ 1556 NLG5_W_OD "LED Output driver defective, LEDs can´t be controlled by NLG5 anymore. Charging is still possible.
";
CM_ SG_ 1556 NLG5_W_CM_NA "NLG5 Control message not active";
CM_ SG_ 1556 NLG5_W_C_VOR "Commanded value is out of specified range; max or min applicable value is assumed instead";
CM_ SG_ 1556 NLG5_W_PL_IT "Output power limited by charger internal overtemperature";
CM_ SG_ 1556 NLG5_W_PL_BV "Output power limited by low battery voltage";
CM_ SG_ 1556 NLG5_W_PL_MV "Output power limited by low mains voltage";
CM_ SG_ 1556 NLG5_E_SDT_CT "Emergency Shutdown Threshold 'Charging Time' is exceeded; see ChargeStar help section 'protective features';  error can only be cleared by cycling power ON-OFF-ON";
CM_ SG_ 1556 NLG5_E_SDT_AH "Emergency Shutdown Threshold 'Amp Hours' is exceeded; see ChargeStar help section 'protective features';  error can only be cleared by cycling power ON-OFF-ON";
CM_ SG_ 1556 NLG5_E_SDT_BV "Emergency Shutdown Threshold 'Battery Voltage' is exceeded; see ChargeStar help section 'protective features';  error can only be cleared by cycling power ON-OFF-ON";
CM_ SG_ 1556 NLG5_E_SDT_BT "Emergency Shutdown Threshold 'Battery Temperature' is exceeded; see ChargeStar help section 'protective features';  error can only be cleared by cycling power ON-OFF-ON";
CM_ SG_ 1556 NLG5_E_C_RX "CAN receiver buffer >127";
CM_ SG_ 1556 NLG5_E_C_TX "CAN transmit buffer >127";
CM_ SG_ 1556 NLG5_E_C_OFF "CAN off, transmit buffer >255";
CM_ SG_ 1556 NLG5_E_C_TO "CAN timeout, no control message received for >300ms";
CM_ SG_ 1556 NLG5_E_INIT "Initialization error";
CM_ SG_ 1556 NLG5_E_WDT "Internal Watchdog Timeout";
CM_ SG_ 1556 NLG5_E_EP_CRC "Pow EEPROM checksum failure";
CM_ SG_ 1556 NLG5_E_ES_CRC "Sys EEPROM checksum failure";
CM_ SG_ 1556 NLG5_E_NV_CRC "NVSRAM check sum failure; contains most of the scaling & calibration values, CAN ID's and  charging profile etc.";
CM_ SG_ 1556 NLG5_E_F_CRC "Flash memory checksum failure";
CM_ SG_ 1556 NLG5_E_T_EXT3 "Ext. temperature sensor 3 defective (if enabled)";
CM_ SG_ 1556 NLG5_E_T_EXT2 "Ext. temperature sensor 2 defective (if enabled)";
CM_ SG_ 1556 NLG5_E_T_EXT1 "Ext. temperature sensor 1 defective (if enabled)";
CM_ SG_ 1556 NLG5_E_T_TR "Temperature sensor for transformer defective";
CM_ SG_ 1556 NLG5_E_T_DIO "Temperature sensor for diodes defective";
CM_ SG_ 1556 NLG5_E_T_POW "Temperature sensor for prim power stage defective";
CM_ SG_ 1556 NLG5_E_T_C "Temperature sensor for prim capacitor defective";
CM_ SG_ 1556 NLG5_E_B_P "wrong battery polarity;  error can only be cleared by cycling power ON-OFF-ON";
CM_ SG_ 1556 NLG5_E_MF "Mains fuse defective";
CM_ SG_ 1556 NLG5_E_OF "output fuse defective";
CM_ SG_ 1556 NLG5_E_P_MV "plausibility mains voltage measurement wrong";
CM_ SG_ 1556 NLG5_E_P_OM "plausibility battery output voltage measurement wrong";
CM_ SG_ 1556 NLG5_E_SC "power stage short circuit condition detected; error can only be cleared by cycling power ON-OFF-ON";
CM_ SG_ 1556 NLG5_E_MOV_I "Mains overvoltage 1 detected";
CM_ SG_ 1556 NLG5_E_MOV_II "Mains overvoltage 2 detected";
CM_ SG_ 1556 NLG5_E_OOV "battery output overvoltage; error can only be cleared by cycling power ON-OFF-ON 
";
CM_ SG_ 1555 NLG5_TMP_EXT3 "Value of external battery temperature sensor #3 (if connected and enabled)";
CM_ SG_ 1555 NLG5_TEMP_EXT2 "Value of external battery temperature sensor #2 (if connected and enabled)";
CM_ SG_ 1555 NLG5_TMP_EXT1 "Value of external battery temperature sensor #1 (if connected and enabled)";
CM_ SG_ 1555 NLG5_P_TMP "Power stage temperature";
CM_ SG_ 1554 NLG5_OC_BO "output current of the booster (if one is present and active)";
CM_ SG_ 1554 NLG5_AHC_EXT "Charge balance obtained via  Ext. Ah counter connected to DI1 / DI2";
CM_ SG_ 1554 NLG5_ABV "Aux battery voltage";
CM_ SG_ 1554 NLG5_S_MC_M_PI "Value of mains current limit, commanded by the 'power indicator' (PI) analog input signal";
CM_ SG_ 1554 NLG5_S_MC_M_CP "Value of mains current limit, commanded by the control pilot (SAE J1772) signal";
CM_ SG_ 1553 NLG5_OC_ACT "output current to the battery";
CM_ SG_ 1553 NLG5_OV_ACT "Actual battery output voltage";
CM_ SG_ 1553 NLG5_MV_ACT "Actual mains voltage";
CM_ SG_ 1553 NLG5_MC_ACT "Actual mains current";
CM_ SG_ 1552 NLG5_S_AAC "AUX 12 V Automatic Charging Active";
CM_ SG_ 1552 NLG5_S_L_T_BATT "Output power limited by battery temperature";
CM_ SG_ 1552 NLG5_S_L_T_TR "Output power limited by temperature of transformer";
CM_ SG_ 1552 NLG5_S_L_T_DIO "Output power limited by temperature of diodes";
CM_ SG_ 1552 NLG5_S_L_T_POW "Output power limited by temperature of power stage";
CM_ SG_ 1552 NLG5_S_L_T_CPRIM "Output power limited by temperature of primary capacitors";
CM_ SG_ 1552 NLG5_S_L_MO_MAX "Output power limited by maximum output voltage capability of NLG5";
CM_ SG_ 1552 NLG5_S_L_OC_MAX "Output power limited by maximum output current capability of NLG5";
CM_ SG_ 1552 NLG5_S_L_MC_MAX "Output power limited by maximum mains current capability of NLG5";
CM_ SG_ 1552 NLG5_S_L_PMAX "Output power limited by maximum power capability of NLG5";
CM_ SG_ 1552 NLG5_S_L_CP "Output power limited by control pilot signal (SAE J1772)";
CM_ SG_ 1552 NLG5_S_L_PI "Output power limited by analog input 'power indicator' (PI) limit";
CM_ SG_ 1552 NLG5_S_L_MC "Output power limited by mains current limit";
CM_ SG_ 1552 NLG5_S_L_OC "Output power limited by battery output current limit";
CM_ SG_ 1552 NLG5_S_L_OV "Output power limited by battery output voltage limit";
CM_ SG_ 1552 NLG5_S_BPD_II "Bypass detection bit 2; 00: no bypass, 01: DC bypass detected, 10:AC bypass in phase, 11: AC bypass not in phase";
CM_ SG_ 1552 NLG5_S_BPD_I "Bypass detection bit 1; 00: no bypass, 01: DC bypass detected, 10:AC bypass in phase, 11: AC bypass not in phase";
CM_ SG_ 1552 NLG5_S_CP_DT "Control pilot signal (SAE J1772) detected ";
CM_ SG_ 1552 NLG5_S_UM_II "US mains level 2 (240VAC / 60Hz) detected";
CM_ SG_ 1552 NLG5_S_UM_I "US mains level 1 (120VAC / 60Hz) detected";
CM_ SG_ 1552 NLG5_S_EUM "European mains input detected (230V, 50Hz)";
CM_ SG_ 1552 NLG5_S_FAN "Charger cooling fan is active";
CM_ SG_ 1552 NLG5_S_WAR "Warning condition on, i.e. charging power limited due to any limiting condition; red LED is blinking";
CM_ SG_ 1552 NLG5_S_ERR "An error has been detected, red LED is ON, no power is output";
CM_ SG_ 1552 NLG5_S_HE "Indicates if hardware enabled, i.e. a hi or lo signal is fed to the 'Power On' pin (pin3 of control connector)";
CM_ SG_ 1560 NLG5_OC_COM "Desired battery current. Must always contain a valid value in order to keep on charging.";
CM_ SG_ 1560 NLG5_OV_COM "Desired voltage to be output to the battery. Must always contain a valid value in order to keep on charging.";
CM_ SG_ 1560 NLG5_MC_MAX "Maximum current to be drawn from the mains outlet, usually 16A. Must always contain a valid value in order to keep on charging.";
CM_ SG_ 1560 NLG5_C_MR "Enables CP-State C to request mains voltage";
CM_ SG_ 1560 NLG5_C_CP_V "special signal to tell a charging station equipped with the Control Pilot interface (SAE J1772) to switch on the facility's ventilation (in order to get rid of battery gases like hydrogen, e.g.)";
CM_ SG_ 1560 NLG5_C_C_EL "cycle this value 0-1-0 to clear all latched charger errors ";
CM_ SG_ 1560 NLG5_C_C_EN "Must be ON to enable power stage of the charger";
CM_ BO_ 0 "Start or stop the actual flash procedure, need a request first";
CM_ BO_ 1 "Message used by openblt to receive data data FROM the microcontroller";
CM_ BO_ 2 "Message used by openblt to send data TO the microcontroller";
CM_ BO_ 4 "[LEGACY]: Message used by openblt to receive data data FROM the microcontroller";
CM_ BO_ 5 "[LEGACY]: Message used by openblt to send data TO the microcontroller";
CM_ BO_ 6 "[LEGACY]: Message used by openblt to receive data data FROM the microcontroller";
CM_ BO_ 7 "[LEGACY]: Message used by openblt to send data TO the microcontroller";
CM_ BO_ 8 "[LEGACY]: Message used by openblt to receive data data FROM the microcontroller";
CM_ BO_ 9 "[LEGACY]: Message used by openblt to send data TO the microcontroller";
CM_ BO_ 10 "[LEGACY]: Message used by openblt to receive data data FROM the microcontroller";
CM_ BO_ 11 "[LEGACY]: Message used by openblt to send data TO the microcontroller";
CM_ BO_ 12 "[LEGACY]: Message used by openblt to receive data data FROM the microcontroller";
CM_ BO_ 13 "[LEGACY]: Message used by openblt to send data TO the microcontroller";
CM_ BO_ 14 "[LEGACY]: Message used by openblt to receive data data FROM the microcontroller";
CM_ BO_ 15 "[LEGACY]: Message used by openblt to send data TO the microcontroller";
CM_ BO_ 700 "Steering wheel version: build-time timestamp and canlib build-time timestamp";
CM_ BO_ 701 "Ecu version: build-time timestamp and canlib build-time timestamp";
CM_ BO_ 703 "Telemetry version: build-time timestamp and canlib build-time timestamp";
CM_ BO_ 704 "Telemetry version: build-time timestamp and canlib build-time timestamp";
CM_ BO_ 702 "Hv mainboard version: build-time timestamp and canlib build-time timestamp";
CM_ BO_ 705 "High-Voltage cellboard version: build-time timestamp and canlib build-time timestamp";
CM_ BO_ 32 "[LEGACY]: Mainboard errors";
CM_ BO_ 512 "[LEGACY]: Mainboard debug signals";
CM_ BO_ 1536 "[LEGACY]: Status of the fans";
CM_ BO_ 1024 "[LEGACY]: Set the status of the fans";
CM_ BO_ 520 "Status of all the BMS HV feedbacks";
CM_ BO_ 528 "[LEGACY]: Feedback TS voltage";
CM_ BO_ 536 "[LEGACY]: Feedback MISC voltage";
CM_ BO_ 544 "[LEGACY]: Feedback SD voltage";
CM_ BO_ 552 "Internal status of the IMD";
CM_ BO_ 560 "Mainboard and cellboard internal FSM status";
CM_ BO_ 48 "Change the mainboard status from the handcart";
CM_ BO_ 1032 "Start or stop the balancing procedure";
CM_ BO_ 1040 "Start or stop the balancing procedure";
CM_ BO_ 680 "Torques and signals calculated by the controls algorithms";
CM_ BO_ 688 "Power maps used by the control algorithm. (ECU checks if are coherent with the ones in the ECU)";
CM_ BO_ 1680 "Mainboard current in A";
CM_ BO_ 1688 "Mainboard power in kW";
CM_ BO_ 1696 "[LEGACY]: Energy of the HV battery pack";
CM_ BO_ 1712 "[LEGACY]: mainboard TS voltage";
CM_ BO_ 1720 "HV cells voltages in V";
CM_ BO_ 1728 "[LEGACY]: Cellboard cells voltages statistics";
CM_ BO_ 1736 "[LEGACY]: Cellboard cells temperature";
CM_ BO_ 1744 "[LEGACY]: Cellboard cells temperature statistics";
CM_ BO_ 50 "Flash procedure request for a single board of the High-Voltage BMS";
CM_ BO_ 51 "Reponse to a flash request";
CM_ BO_ 1112 "Voltage present on the tractive system in V";
CM_ BO_ 1832 "HV cells temperatures in Â°C";
CM_ BO_ 1840 "HV cellboard discharge resistor temperatures in Â°C";
CM_ BO_ 1848 "HV cooling temperatures in Â°C";
CM_ BO_ 696 "Values of the BMS HV digital feedbacks";
CM_ BO_ 712 "Voltages of the BMS HV analog feedbacks";
CM_ BO_ 720 "Voltages of the BMS HV analog shutdown circuit feedbacks";
CM_ BO_ 728 "Info regarding the feedback that did not allow the BMS to go in the TS ON state";
CM_ BO_ 736 "Info regarding the error which has occoured";
BA_DEF_  "Bus Speed" STRING ;
BA_DEF_ SG_  "GenSigSendType" ENUM  "Cyclic","OnWrite","OnWriteWithRepetition","OnChange","OnChangeWithRepetition","IfActive","IfActiveWithRepetition","NoSigSendType";
BA_DEF_ BO_  "GenMsgCycleTime" INT 0 0;
BA_DEF_ BO_  "GenMsgSendType" ENUM  "Cyclic","not_used","not_used","not_used","not_used","Cyclic","not_used","IfActive","NoMsgSendType";
BA_DEF_  "DBName" STRING ;
BA_DEF_  "BusType" STRING ;
BA_DEF_DEF_  "Bus Speed" "500k";
BA_DEF_DEF_  "GenSigSendType" "Cyclic";
BA_DEF_DEF_  "GenMsgCycleTime" 0;
BA_DEF_DEF_  "GenMsgSendType" "NoMsgSendType";
BA_DEF_DEF_  "DBName" "";
BA_DEF_DEF_  "BusType" "CAN";
BA_ "DBName" "CANTemplate";
BA_ "GenMsgCycleTime" BO_ 0 200;
BA_ "GenMsgCycleTime" BO_ 700 1000;
BA_ "GenMsgCycleTime" BO_ 701 1000;
BA_ "GenMsgCycleTime" BO_ 703 1000;
BA_ "GenMsgCycleTime" BO_ 704 1000;
BA_ "GenMsgCycleTime" BO_ 702 1000;
BA_ "GenMsgCycleTime" BO_ 705 1000;
BA_ "GenMsgCycleTime" BO_ 32 20;
BA_ "GenMsgCycleTime" BO_ 512 500;
BA_ "GenMsgCycleTime" BO_ 1536 200;
BA_ "GenMsgCycleTime" BO_ 1024 200;
BA_ "GenMsgCycleTime" BO_ 520 50;
BA_ "GenMsgCycleTime" BO_ 528 50;
BA_ "GenMsgCycleTime" BO_ 536 50;
BA_ "GenMsgCycleTime" BO_ 544 50;
BA_ "GenMsgCycleTime" BO_ 552 20;
BA_ "GenMsgCycleTime" BO_ 560 20;
BA_ "GenMsgCycleTime" BO_ 40 50;
BA_ "GenMsgCycleTime" BO_ 48 50;
BA_ "GenMsgCycleTime" BO_ 1544 50;
BA_ "GenMsgCycleTime" BO_ 1032 200;
BA_ "GenMsgCycleTime" BO_ 1040 200;
BA_ "GenMsgCycleTime" BO_ 568 20;
BA_ "GenMsgCycleTime" BO_ 1568 200;
BA_ "GenMsgCycleTime" BO_ 1576 1000;
BA_ "GenMsgCycleTime" BO_ 1584 200;
BA_ "GenMsgCycleTime" BO_ 1592 200;
BA_ "GenMsgCycleTime" BO_ 1056 200;
BA_ "GenMsgCycleTime" BO_ 1064 200;
BA_ "GenMsgCycleTime" BO_ 576 20;
BA_ "GenMsgCycleTime" BO_ 584 50;
BA_ "GenMsgCycleTime" BO_ 592 50;
BA_ "GenMsgCycleTime" BO_ 600 50;
BA_ "GenMsgCycleTime" BO_ 608 50;
BA_ "GenMsgCycleTime" BO_ 616 50;
BA_ "GenMsgCycleTime" BO_ 624 20;
BA_ "GenMsgCycleTime" BO_ 80 50;
BA_ "GenMsgCycleTime" BO_ 1600 200;
BA_ "GenMsgCycleTime" BO_ 1072 200;
BA_ "GenMsgCycleTime" BO_ 632 20;
BA_ "GenMsgCycleTime" BO_ 1608 200;
BA_ "GenMsgCycleTime" BO_ 1080 200;
BA_ "GenMsgCycleTime" BO_ 640 20;
BA_ "GenMsgCycleTime" BO_ 88 50;
BA_ "GenMsgCycleTime" BO_ 1088 50;
BA_ "GenMsgCycleTime" BO_ 648 50;
BA_ "GenMsgCycleTime" BO_ 656 20;
BA_ "GenMsgCycleTime" BO_ 664 50;
BA_ "GenMsgCycleTime" BO_ 672 200;
BA_ "GenMsgCycleTime" BO_ 96 200;
BA_ "GenMsgCycleTime" BO_ 1616 200;
BA_ "GenMsgCycleTime" BO_ 1096 200;
BA_ "GenMsgCycleTime" BO_ 513 10;
BA_ "GenMsgCycleTime" BO_ 680 20;
BA_ "GenMsgCycleTime" BO_ 688 20;
BA_ "GenMsgCycleTime" BO_ 514 10;
BA_ "GenMsgCycleTime" BO_ 385 100;
BA_ "GenMsgCycleTime" BO_ 386 100;
BA_ "GenMsgCycleTime" BO_ 1624 50;
BA_ "GenMsgCycleTime" BO_ 1632 50;
BA_ "GenMsgCycleTime" BO_ 1640 50;
BA_ "GenMsgCycleTime" BO_ 1648 50;
BA_ "GenMsgCycleTime" BO_ 1656 50;
BA_ "GenMsgCycleTime" BO_ 1664 50;
BA_ "GenMsgCycleTime" BO_ 1672 50;
BA_ "GenMsgCycleTime" BO_ 1680 50;
BA_ "GenMsgCycleTime" BO_ 1688 50;
BA_ "GenMsgCycleTime" BO_ 1696 50;
BA_ "GenMsgCycleTime" BO_ 1704 50;
BA_ "GenMsgCycleTime" BO_ 1712 50;
BA_ "GenMsgCycleTime" BO_ 1720 50;
BA_ "GenMsgCycleTime" BO_ 1728 50;
BA_ "GenMsgCycleTime" BO_ 1736 50;
BA_ "GenMsgCycleTime" BO_ 1744 50;
BA_ "GenMsgCycleTime" BO_ 1752 200;
BA_ "GenMsgCycleTime" BO_ 1104 200;
BA_ "GenMsgCycleTime" BO_ 1760 50;
BA_ "GenMsgCycleTime" BO_ 1768 200;
BA_ "GenMsgCycleTime" BO_ 1776 10;
BA_ "GenMsgCycleTime" BO_ 1784 10;
BA_ "GenMsgCycleTime" BO_ 1792 20;
BA_ "GenMsgCycleTime" BO_ 1800 20;
BA_ "GenMsgCycleTime" BO_ 1808 20;
BA_ "GenMsgCycleTime" BO_ 1824 20;
BA_ "GenMsgCycleTime" BO_ 1112 50;
BA_ "GenMsgCycleTime" BO_ 1832 50;
BA_ "GenMsgCycleTime" BO_ 1840 50;
BA_ "GenMsgCycleTime" BO_ 1848 200;
BA_ "GenMsgCycleTime" BO_ 256 100;
BA_ "GenMsgCycleTime" BO_ 272 100;
BA_ "GenMsgCycleTime" BO_ 288 1000;
BA_ "GenMsgCycleTime" BO_ 304 100;
BA_ "GenMsgCycleTime" BO_ 320 1000;
BA_ "GenMsgCycleTime" BO_ 336 1000;
BA_ "GenMsgCycleTime" BO_ 344 1000;
BA_ "GenMsgCycleTime" BO_ 352 1000;
BA_ "GenMsgCycleTime" BO_ 368 1000;
BA_ "GenMsgCycleTime" BO_ 384 1000;
BA_ "GenMsgCycleTime" BO_ 392 1000;
BA_ "GenMsgCycleTime" BO_ 400 1000;
BA_ "GenMsgCycleTime" BO_ 408 1000;
BA_ "GenMsgCycleTime" BO_ 416 1000;
BA_ "GenMsgCycleTime" BO_ 432 1000;
BA_ "GenMsgCycleTime" BO_ 448 1000;
BA_ "GenMsgCycleTime" BO_ 464 1000;
BA_ "GenMsgCycleTime" BO_ 480 1000;
BA_ "GenMsgCycleTime" BO_ 496 1000;
BA_ "GenMsgCycleTime" BO_ 696 50;
BA_ "GenMsgCycleTime" BO_ 712 50;
BA_ "GenMsgCycleTime" BO_ 720 50;
BA_ "GenMsgCycleTime" BO_ 736 20;
VAL_ 0 cellboard_id 0 "cellboard_0" 1 "cellboard_1" 2 "cellboard_2" 3 "cellboard_3" 4 "cellboard_4" 5 "cellboard_5" ;
VAL_ 0 forward 0 "off" 1 "on" ;
VAL_ 705 cellboard_id 0 "cellboard_0" 1 "cellboard_1" 2 "cellboard_2" 3 "cellboard_3" 4 "cellboard_4" 5 "cellboard_5" ;
VAL_ 1536 fans_override 0 "off" 1 "on" ;
VAL_ 1024 fans_override 0 "off" 1 "on" ;
VAL_ 520 feedback_check_mux 0 "low" 1 "error" 2 "high" ;
VAL_ 520 feedback_tsp_over_60v_status 0 "low" 1 "error" 2 "high" ;
VAL_ 520 feedback_precharge_status 0 "low" 1 "error" 2 "high" ;
VAL_ 520 feedback_ext_latched 0 "low" 1 "error" 2 "high" ;
VAL_ 520 feedback_tsal_green_fault_latched 0 "low" 1 "error" 2 "high" ;
VAL_ 520 v5_mcu 0 "low" 1 "error" 2 "high" ;
VAL_ 520 sd_end 0 "low" 1 "error" 2 "high" ;
VAL_ 520 sd_in 0 "low" 1 "error" 2 "high" ;
VAL_ 520 sd_out 0 "low" 1 "error" 2 "high" ;
VAL_ 520 probing_3v3 0 "low" 1 "error" 2 "high" ;
VAL_ 520 tsal_green 0 "low" 1 "error" 2 "high" ;
VAL_ 520 plausible_state_rc 0 "low" 1 "error" 2 "high" ;
VAL_ 520 imd_ok 0 "low" 1 "error" 2 "high" ;
VAL_ 520 not_ext_fault_latched 0 "low" 1 "error" 2 "high" ;
VAL_ 520 not_imd_fault_latched 0 "low" 1 "error" 2 "high" ;
VAL_ 520 not_bms_fault_latched 0 "low" 1 "error" 2 "high" ;
VAL_ 520 plausible_state_latched 0 "low" 1 "error" 2 "high" ;
VAL_ 520 not_latch_reset 0 "low" 1 "error" 2 "high" ;
VAL_ 520 indicator_connected 0 "low" 1 "error" 2 "high" ;
VAL_ 520 not_imd_fault_cockpit_led 0 "low" 1 "error" 2 "high" ;
VAL_ 520 not_bms_fault_cockpit_led 0 "low" 1 "error" 2 "high" ;
VAL_ 520 plausible_state 0 "low" 1 "error" 2 "high" ;
VAL_ 520 plausible_state_persisted 0 "low" 1 "error" 2 "high" ;
VAL_ 520 ts_less_than_60v 0 "low" 1 "error" 2 "high" ;
VAL_ 520 sd_bms_fb 0 "low" 1 "error" 2 "high" ;
VAL_ 520 sd_imd_fb 0 "low" 1 "error" 2 "high" ;
VAL_ 520 airp_open_mec 0 "low" 1 "error" 2 "high" ;
VAL_ 520 precharge_open_mec 0 "low" 1 "error" 2 "high" ;
VAL_ 520 airn_open_mec 0 "low" 1 "error" 2 "high" ;
VAL_ 520 airp_open_com 0 "low" 1 "error" 2 "high" ;
VAL_ 520 precharge_open_com 0 "low" 1 "error" 2 "high" ;
VAL_ 520 airn_open_com 0 "low" 1 "error" 2 "high" ;
VAL_ 552 feedback_not_imd_fault_latched 0 "low" 1 "error" 2 "high" ;
VAL_ 552 feedback_not_imd_fault_cockpit_led 0 "low" 1 "error" 2 "high" ;
VAL_ 552 status 0 "unknown" 1 "short_circuit" 2 "normal" 3 "under_voltage" 4 "start_measure" 5 "device_error" 6 "earth_fault" ;
VAL_ 560 cellboard_5 0 "init" 1 "idle" 2 "fatal" 3 "flash" 4 "discharge" 5 "cooldown" ;
VAL_ 560 cellboard_4 0 "init" 1 "idle" 2 "fatal" 3 "flash" 4 "discharge" 5 "cooldown" ;
VAL_ 560 cellboard_3 0 "init" 1 "idle" 2 "fatal" 3 "flash" 4 "discharge" 5 "cooldown" ;
VAL_ 560 cellboard_2 0 "init" 1 "idle" 2 "fatal" 3 "flash" 4 "discharge" 5 "cooldown" ;
VAL_ 560 cellboard_1 0 "init" 1 "idle" 2 "fatal" 3 "flash" 4 "discharge" 5 "cooldown" ;
VAL_ 560 cellboard_0 0 "init" 1 "idle" 2 "fatal" 3 "flash" 4 "discharge" 5 "cooldown" ;
VAL_ 560 status 0 "init" 1 "idle" 2 "fatal" 3 "flash" 4 "balancing" 5 "airn_check" 6 "precharge_check" 7 "airp_check" 8 "ts_on" ;
VAL_ 40 hv_status_set 0 "off" 1 "on" ;
VAL_ 48 hv_status_set 0 "off" 1 "on" ;
VAL_ 1544 status 0 "stopped" 1 "paused" 2 "running" ;
VAL_ 1544 balancing_status 0 "off" 1 "on" ;
VAL_ 1544 cellboard_id 0 "cellboard_0" 1 "cellboard_1" 2 "cellboard_2" 3 "cellboard_3" 4 "cellboard_4" 5 "cellboard_5" ;
VAL_ 1032 set_balancing_status 0 "off" 1 "on" ;
VAL_ 1040 set_balancing_status 0 "off" 1 "on" ;
VAL_ 568 status 0 "init" 1 "idle" 2 "tson" 3 "run" 4 "flashing" 5 "error" ;
VAL_ 1568 status 0 "off" 1 "on" ;
VAL_ 1576 status 0 "weak" 1 "normal" 2 "aggressive" ;
VAL_ 1048 status 0 "weak" 1 "normal" 2 "aggressive" ;
VAL_ 1584 status 0 "off" 1 "auto" 2 "manual" ;
VAL_ 1592 status 0 "off" 1 "auto" 2 "manual" ;
VAL_ 1056 status 0 "off" 1 "auto" 2 "manual" ;
VAL_ 1064 status 0 "off" 1 "auto" 2 "manual" ;
VAL_ 624 status 0 "off" 1 "on" ;
VAL_ 80 status 0 "off" 1 "on" ;
VAL_ 1600 status 0 "off" 1 "on" ;
VAL_ 1072 status 0 "off" 1 "on" ;
VAL_ 632 connected 0 "off" 1 "on" ;
VAL_ 1608 status 0 "none" 1 "check" 2 "idle" 3 "precharge" 4 "ready" 5 "charge" 6 "charge_done" 7 "balancing" 8 "error" ;
VAL_ 1608 fans_override 0 "off" 1 "on" ;
VAL_ 1080 status 0 "none" 1 "check" 2 "idle" 3 "precharge" 4 "ready" 5 "charge" 6 "charge_done" 7 "balancing" 8 "error" ;
VAL_ 1080 fans_override 0 "off" 1 "on" ;
VAL_ 640 status 0 "init" 1 "enable_inv_updates" 2 "check_inv_settings" 3 "idle" 4 "start_ts_precharge" 5 "wait_ts_precharge" 6 "wait_driver" 7 "enable_inv_drive" 8 "drive" 9 "disable_inv_drive" 10 "start_ts_discharge" 11 "re_enable_inverter_drive" 12 "wait_ts_discharge" 13 "fatal_error" ;
VAL_ 88 status 0 "idle" 1 "ready" 2 "drive" ;
VAL_ 1088 rr 0 "disabled" 1 "rfe_on" 2 "frg_on" 3 "enabled" ;
VAL_ 1088 rl 0 "disabled" 1 "rfe_on" 2 "frg_on" 3 "enabled" ;
VAL_ 672 reg_state 0 "off" 1 "on" ;
VAL_ 672 tv_state 0 "off" 1 "on" ;
VAL_ 672 sc_state 0 "off" 1 "on" ;
VAL_ 96 reg_state 0 "off" 1 "on" ;
VAL_ 96 tv_state 0 "off" 1 "on" ;
VAL_ 96 sc_state 0 "off" 1 "on" ;
VAL_ 1616 status 0 "off" 1 "on" ;
VAL_ 1096 status 0 "off" 1 "on" ;
VAL_ 688 reg_state 0 "off" 1 "on" ;
VAL_ 688 tv_state 0 "off" 1 "on" ;
VAL_ 688 sc_state 0 "off" 1 "on" ;
VAL_ 1720 cellboard_id 0 "cellboard_0" 1 "cellboard_1" 2 "cellboard_2" 3 "cellboard_3" 4 "cellboard_4" 5 "cellboard_5" ;
VAL_ 1752 brakeStatus 0 "off" 1 "on" ;
VAL_ 1752 throttleStatus 0 "off" 1 "on" ;
VAL_ 1752 steerStatus 0 "off" 1 "on" ;
VAL_ 1104 brakeStatus 0 "off" 1 "on" ;
VAL_ 1104 throttleStatus 0 "off" 1 "on" ;
VAL_ 1104 steerStatus 0 "off" 1 "on" ;
VAL_ 1792 device_id 0 "hv_mainboard" 1 "hv_cellboard" 2 "lv" 3 "ecu" 4 "tlm" 5 "traction_control" 6 "steeering_wheel" 7 "handcart" 8 "acquisinator" ;
VAL_ 1800 device_id 0 "hv_mainboard" 1 "hv_cellboard" 2 "lv" 3 "ecu" 4 "tlm" 5 "traction_control" 6 "steeering_wheel" 7 "handcart" 8 "acquisinator" ;
VAL_ 1808 device_id 0 "hv_mainboard" 1 "hv_cellboard" 2 "lv" 3 "ecu" 4 "tlm" 5 "traction_control" 6 "steeering_wheel" 7 "handcart" 8 "acquisinator" ;
VAL_ 1824 device_id 0 "hv_mainboard" 1 "hv_cellboard" 2 "lv" 3 "ecu" 4 "tlm" 5 "traction_control" 6 "steeering_wheel" 7 "handcart" 8 "acquisinator" ;
VAL_ 50 cellboard_id 0 "cellboard_0" 1 "cellboard_1" 2 "cellboard_2" 3 "cellboard_3" 4 "cellboard_4" 5 "cellboard_5" ;
VAL_ 1832 cellboard_id 0 "cellboard_0" 1 "cellboard_1" 2 "cellboard_2" 3 "cellboard_3" 4 "cellboard_4" 5 "cellboard_5" ;
VAL_ 1840 cellboard_id 0 "cellboard_0" 1 "cellboard_1" 2 "cellboard_2" 3 "cellboard_3" 4 "cellboard_4" 5 "cellboard_5" ;
VAL_ 728 status 0 "low" 1 "error" 2 "high" ;
VAL_ 728 feedback 0 "airn_open_com" 1 "precharge_open_com" 2 "airp_open_com" 3 "airn_open_mec" 4 "precharge_open_mec" 5 "airp_open_mec" 6 "sd_imd_fb" 7 "sd_bms_fb" 8 "ts_less_than_60v" 9 "plausible_state_persisted" 10 "plausible_state" 11 "not_bms_fault_cockpit_led" 12 "not_imd_fault_cockpit_led" 13 "indicator_connected" 14 "not_latch_reset" 15 "plausible_state_latched" 16 "not_bms_fault_latched" 17 "not_imd_fault_latched" 18 "not_ext_fault_latched" 19 "imd_ok" 20 "plausible_state_rc" 21 "tsal_green" 22 "probing_3v3" 23 "sd_out" 24 "sd_in" 25 "sd_end" 26 "v5_mcu" 27 "unknown" ;
VAL_ 736 cellboard_group 0 "post" 1 "under_voltage" 2 "over_voltage" 3 "under_temperature_cells" 4 "over_temperature_cells" 5 "under_temperature_discharge" 6 "over_temperature_discharge" 7 "can_communication" 8 "flash" 9 "bms_monitor_communication" 10 "open_wire" ;
VAL_ 736 cellboard_id 0 "cellboard_0" 1 "cellboard_1" 2 "cellboard_2" 3 "cellboard_3" 4 "cellboard_4" 5 "cellboard_5" ;
VAL_ 736 group 0 "post" 1 "over_current" 2 "over_power" 3 "under_voltage" 4 "over_voltage" 5 "under_temperature" 6 "over_temperature" 7 "can_communication" 8 "current_sensor_communication" 9 "cooling_under_temperature" 10 "cooling_over_temperature" 11 "cellboard_error" ;
